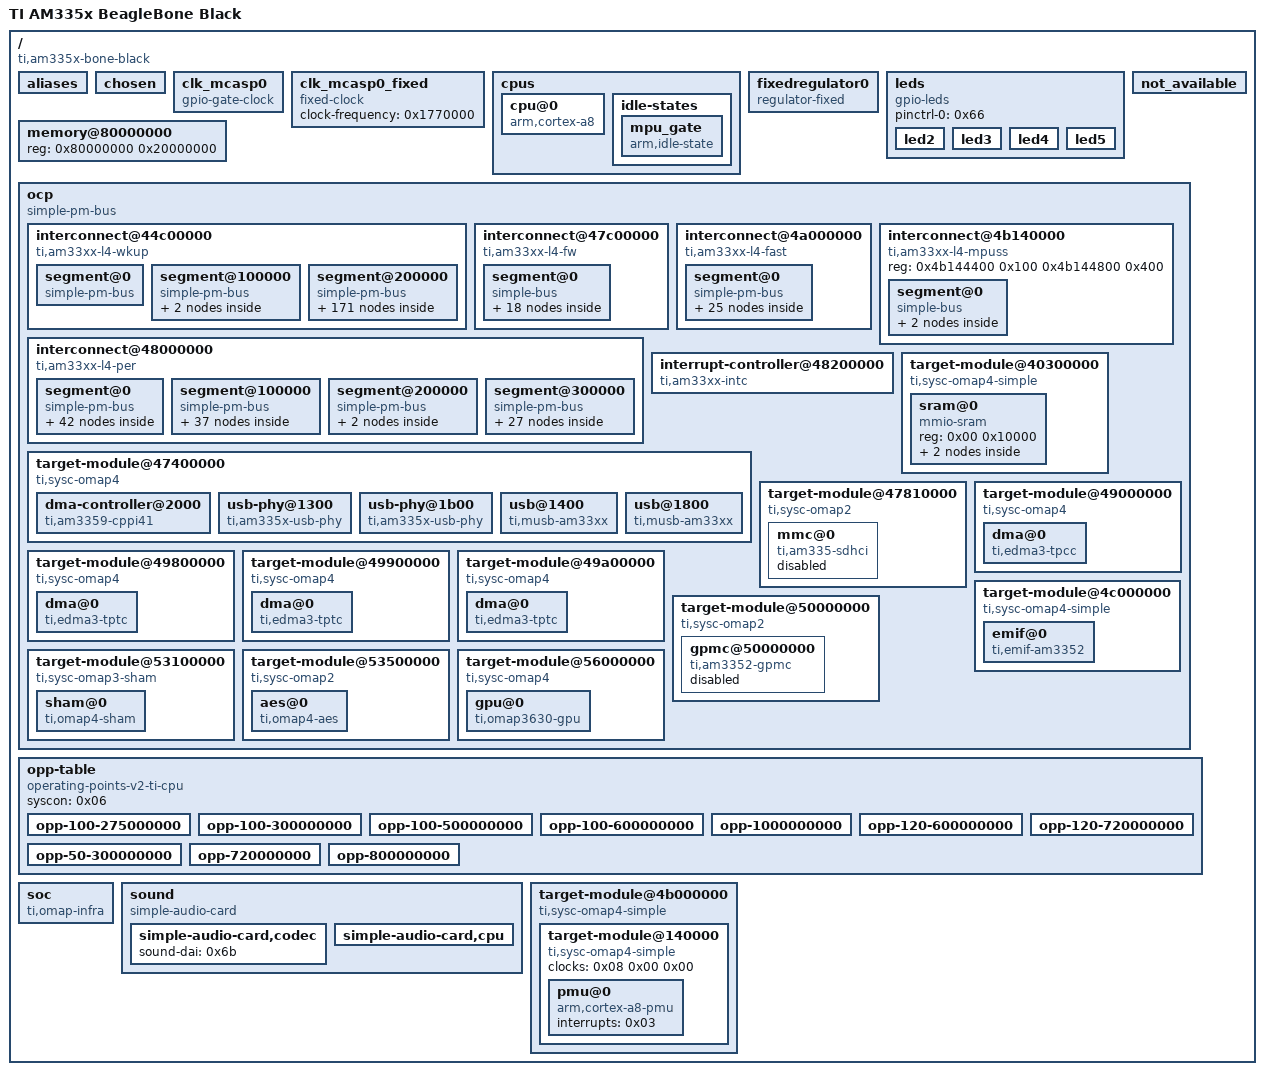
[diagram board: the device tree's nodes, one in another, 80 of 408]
/dts-v1/;

/ {
	#address-cells = <0x01>;
	#size-cells = <0x01>;
	compatible = "ti,am335x-bone-black\0ti,am335x-bone\0ti,am33xx";
	interrupt-parent = <0x01>;
	model = "TI AM335x BeagleBone Black";

	__symbols__ {
		adc_tsc_fck = "/ocp/interconnect@44c00000/segment@200000/target-module@10000/scm@0/scm_conf@0/clocks/clock-adc-tsc-fck";
		aes = "/ocp/target-module@53500000/aes@0";
		aes0_fck = "/ocp/interconnect@44c00000/segment@200000/target-module@10000/scm@0/scm_conf@0/clocks/clock-aes0-fck";
		aes_target = "/ocp/target-module@53500000";
		am335x_adc = "/ocp/interconnect@44c00000/segment@200000/target-module@d000/tscadc@0/adc";
		am33xx_pinmux = "/ocp/interconnect@44c00000/segment@200000/target-module@10000/scm@0/pinmux@800";
		baseboard_data = "/ocp/interconnect@44c00000/segment@200000/target-module@b000/i2c@0/eeprom@50/nvmem-layout/baseboard_data@0";
		baseboard_eeprom = "/ocp/interconnect@44c00000/segment@200000/target-module@b000/i2c@0/eeprom@50";
		bborg_comms_can_pins = "/ocp/interconnect@44c00000/segment@200000/target-module@10000/scm@0/pinmux@800/pinmux_comms_can_pins";
		bborg_comms_rs485_pins = "/ocp/interconnect@44c00000/segment@200000/target-module@10000/scm@0/pinmux@800/pinmux_comms_rs485_pins";
		bone_adc = "/ocp/interconnect@44c00000/segment@200000/target-module@d000/tscadc@0";
		bone_can_1 = "/ocp/interconnect@48000000/segment@100000/target-module@d0000/can@0";
		bone_pinmux = "/ocp/interconnect@44c00000/segment@200000/target-module@10000/scm@0/pinmux@800";
		bone_uart_4 = "/ocp/interconnect@48000000/segment@100000/target-module@a8000/serial@0";
		cape0_data = "/ocp/interconnect@48000000/segment@100000/target-module@9c000/i2c@0/eeprom@54/nvmem-layout/cape_data@0";
		cape1_data = "/ocp/interconnect@48000000/segment@100000/target-module@9c000/i2c@0/eeprom@55/nvmem-layout/cape_data@0";
		cape2_data = "/ocp/interconnect@48000000/segment@100000/target-module@9c000/i2c@0/eeprom@56/nvmem-layout/cape_data@0";
		cape3_data = "/ocp/interconnect@48000000/segment@100000/target-module@9c000/i2c@0/eeprom@57/nvmem-layout/cape_data@0";
		cape_eeprom0 = "/ocp/interconnect@48000000/segment@100000/target-module@9c000/i2c@0/eeprom@54";
		cape_eeprom1 = "/ocp/interconnect@48000000/segment@100000/target-module@9c000/i2c@0/eeprom@55";
		cape_eeprom2 = "/ocp/interconnect@48000000/segment@100000/target-module@9c000/i2c@0/eeprom@56";
		cape_eeprom3 = "/ocp/interconnect@48000000/segment@100000/target-module@9c000/i2c@0/eeprom@57";
		clk_24mhz = "/ocp/interconnect@44c00000/segment@200000/target-module@0/prcm@0/clocks/clock-clk-24mhz";
		clk_24mhz_clkctrl = "/ocp/interconnect@44c00000/segment@200000/target-module@0/prcm@0/clock@0/clock@14c";
		clk_32768_ck = "/ocp/interconnect@44c00000/segment@200000/target-module@0/prcm@0/clocks/clock-clk-32768";
		clk_mcasp0 = "/clk_mcasp0";
		clk_mcasp0_fixed = "/clk_mcasp0_fixed";
		clk_rc32k_ck = "/ocp/interconnect@44c00000/segment@200000/target-module@0/prcm@0/clocks/clock-clk-rc32k";
		clkdiv32k_ck = "/ocp/interconnect@44c00000/segment@200000/target-module@0/prcm@0/clocks/clock-clkdiv32k";
		clkout2_ck = "/ocp/interconnect@44c00000/segment@200000/target-module@0/prcm@0/clocks/clock@700/clock-clkout2@7";
		clkout2_div_ck = "/ocp/interconnect@44c00000/segment@200000/target-module@0/prcm@0/clocks/clock@700/clock-clkout2-div@3";
		cppi41dma = "/ocp/target-module@47400000/dma-controller@2000";
		cpsw_125mhz_clkctrl = "/ocp/interconnect@44c00000/segment@200000/target-module@0/prcm@0/clock@0/clock@0";
		cpsw_125mhz_gclk = "/ocp/interconnect@44c00000/segment@200000/target-module@0/prcm@0/clocks/clock-cpsw-125mhz-gclk";
		cpsw_cpts_rft_clk = "/ocp/interconnect@44c00000/segment@200000/target-module@0/prcm@0/clocks/clock-cpsw-cpts-rft@520";
		cpsw_default = "/ocp/interconnect@44c00000/segment@200000/target-module@10000/scm@0/pinmux@800/cpsw-default-pins";
		cpsw_emac0 = "/ocp/interconnect@4a000000/segment@0/target-module@100000/ethernet@0/slave@200";
		cpsw_emac1 = "/ocp/interconnect@4a000000/segment@0/target-module@100000/ethernet@0/slave@300";
		cpsw_port1 = "/ocp/interconnect@4a000000/segment@0/target-module@100000/switch@0/ethernet-ports/port@1";
		cpsw_port2 = "/ocp/interconnect@4a000000/segment@0/target-module@100000/switch@0/ethernet-ports/port@2";
		cpsw_sleep = "/ocp/interconnect@44c00000/segment@200000/target-module@10000/scm@0/pinmux@800/cpsw-sleep-pins";
		cpu = "/cpus/cpu@0";
		cpu0_opp_table = "/opp-table";
		dailink0_master = "/sound/simple-audio-card,cpu";
		davinci_mdio = "/ocp/interconnect@4a000000/segment@0/target-module@100000/ethernet@0/mdio@1000";
		davinci_mdio_default = "/ocp/interconnect@44c00000/segment@200000/target-module@10000/scm@0/pinmux@800/davinci-mdio-default-pins";
		davinci_mdio_sleep = "/ocp/interconnect@44c00000/segment@200000/target-module@10000/scm@0/pinmux@800/davinci-mdio-sleep-pins";
		davinci_mdio_sw = "/ocp/interconnect@4a000000/segment@0/target-module@100000/switch@0/mdio@1000";
		dcan0 = "/ocp/interconnect@48000000/segment@100000/target-module@cc000/can@0";
		dcan0_fck = "/ocp/interconnect@44c00000/segment@200000/target-module@10000/scm@0/scm_conf@0/clocks/clock-dcan0-fck";
		dcan1 = "/ocp/interconnect@48000000/segment@100000/target-module@d0000/can@0";
		dcan1_fck = "/ocp/interconnect@44c00000/segment@200000/target-module@10000/scm@0/scm_conf@0/clocks/clock-dcan1-fck";
		dcdc1_reg = "/ocp/interconnect@44c00000/segment@200000/target-module@b000/i2c@0/pmic@24/regulators/regulator@0";
		dcdc2_reg = "/ocp/interconnect@44c00000/segment@200000/target-module@b000/i2c@0/pmic@24/regulators/regulator@1";
		dcdc3_reg = "/ocp/interconnect@44c00000/segment@200000/target-module@b000/i2c@0/pmic@24/regulators/regulator@2";
		dpll_core_ck = "/ocp/interconnect@44c00000/segment@200000/target-module@0/prcm@0/clocks/clock@490";
		dpll_core_m4_ck = "/ocp/interconnect@44c00000/segment@200000/target-module@0/prcm@0/clocks/clock-dpll-core-m4@480";
		dpll_core_m4_div2_ck = "/ocp/interconnect@44c00000/segment@200000/target-module@0/prcm@0/clocks/clock-dpll-core-m4-div2";
		dpll_core_m5_ck = "/ocp/interconnect@44c00000/segment@200000/target-module@0/prcm@0/clocks/clock-dpll-core-m5@484";
		dpll_core_m6_ck = "/ocp/interconnect@44c00000/segment@200000/target-module@0/prcm@0/clocks/clock-dpll-core-m6@4d8";
		dpll_core_x2_ck = "/ocp/interconnect@44c00000/segment@200000/target-module@0/prcm@0/clocks/clock-dpll-core-x2";
		dpll_ddr_ck = "/ocp/interconnect@44c00000/segment@200000/target-module@0/prcm@0/clocks/clock@494";
		dpll_ddr_m2_ck = "/ocp/interconnect@44c00000/segment@200000/target-module@0/prcm@0/clocks/clock-dpll-ddr-m2@4a0";
		dpll_ddr_m2_div2_ck = "/ocp/interconnect@44c00000/segment@200000/target-module@0/prcm@0/clocks/clock-dpll-ddr-m2-div2";
		dpll_disp_ck = "/ocp/interconnect@44c00000/segment@200000/target-module@0/prcm@0/clocks/clock@498";
		dpll_disp_m2_ck = "/ocp/interconnect@44c00000/segment@200000/target-module@0/prcm@0/clocks/clock-dpll-disp-m2@4a4";
		dpll_mpu_ck = "/ocp/interconnect@44c00000/segment@200000/target-module@0/prcm@0/clocks/clock@488";
		dpll_mpu_m2_ck = "/ocp/interconnect@44c00000/segment@200000/target-module@0/prcm@0/clocks/clock-dpll-mpu-m2@4a8";
		dpll_per_ck = "/ocp/interconnect@44c00000/segment@200000/target-module@0/prcm@0/clocks/clock@48c";
		dpll_per_m2_ck = "/ocp/interconnect@44c00000/segment@200000/target-module@0/prcm@0/clocks/clock-dpll-per-m2@4ac";
		dpll_per_m2_div4_ck = "/ocp/interconnect@44c00000/segment@200000/target-module@0/prcm@0/clocks/clock-dpll-per-m2-div4";
		dpll_per_m2_div4_wkupdm_ck = "/ocp/interconnect@44c00000/segment@200000/target-module@0/prcm@0/clocks/clock-dpll-per-m2-div4-wkupdm";
		ecap0 = "/ocp/interconnect@48000000/segment@300000/target-module@0/epwmss@0/pwm@100";
		ecap1 = "/ocp/interconnect@48000000/segment@300000/target-module@2000/epwmss@0/pwm@100";
		ecap2 = "/ocp/interconnect@48000000/segment@300000/target-module@4000/epwmss@0/pwm@100";
		edma = "/ocp/target-module@49000000/dma@0";
		edma_tptc0 = "/ocp/target-module@49800000/dma@0";
		edma_tptc1 = "/ocp/target-module@49900000/dma@0";
		edma_tptc2 = "/ocp/target-module@49a00000/dma@0";
		edma_xbar = "/ocp/interconnect@44c00000/segment@200000/target-module@10000/scm@0/dma-router@f90";
		ehrpwm0 = "/ocp/interconnect@48000000/segment@300000/target-module@0/epwmss@0/pwm@200";
		ehrpwm0_tbclk = "/ocp/interconnect@44c00000/segment@200000/target-module@10000/scm@0/scm_conf@0/clocks/clock@664/clock-ehrpwm0-tbclk@0";
		ehrpwm1 = "/ocp/interconnect@48000000/segment@300000/target-module@2000/epwmss@0/pwm@200";
		ehrpwm1_tbclk = "/ocp/interconnect@44c00000/segment@200000/target-module@10000/scm@0/scm_conf@0/clocks/clock@664/clock-ehrpwm1-tbclk@1";
		ehrpwm2 = "/ocp/interconnect@48000000/segment@300000/target-module@4000/epwmss@0/pwm@200";
		ehrpwm2_tbclk = "/ocp/interconnect@44c00000/segment@200000/target-module@10000/scm@0/scm_conf@0/clocks/clock@664/clock-ehrpwm2-tbclk@2";
		elm = "/ocp/interconnect@48000000/segment@0/target-module@80000/elm@0";
		emif = "/ocp/target-module@4c000000/emif@0";
		emmc_pins = "/ocp/interconnect@44c00000/segment@200000/target-module@10000/scm@0/pinmux@800/emmc-pins";
		epwmss0 = "/ocp/interconnect@48000000/segment@300000/target-module@0/epwmss@0";
		epwmss1 = "/ocp/interconnect@48000000/segment@300000/target-module@2000/epwmss@0";
		epwmss2 = "/ocp/interconnect@48000000/segment@300000/target-module@4000/epwmss@0";
		eqep0 = "/ocp/interconnect@48000000/segment@300000/target-module@0/epwmss@0/counter@180";
		eqep1 = "/ocp/interconnect@48000000/segment@300000/target-module@2000/epwmss@0/counter@180";
		eqep2 = "/ocp/interconnect@48000000/segment@300000/target-module@4000/epwmss@0/counter@180";
		ethphy0 = "/ocp/interconnect@4a000000/segment@0/target-module@100000/switch@0/mdio@1000/ethernet-phy@0";
		gfx_fck_div_ck = "/ocp/interconnect@44c00000/segment@200000/target-module@0/prcm@0/clocks/clock@52c/clock-gfx-fck-div@0";
		gfx_fclk_clksel_ck = "/ocp/interconnect@44c00000/segment@200000/target-module@0/prcm@0/clocks/clock@52c/clock-gfx-fclk-clksel@1";
		gfx_l3_clkctrl = "/ocp/interconnect@44c00000/segment@200000/target-module@0/prcm@0/clock@900/clock@0";
		gfx_l3_cm = "/ocp/interconnect@44c00000/segment@200000/target-module@0/prcm@0/clock@900";
		gpio0 = "/ocp/interconnect@44c00000/segment@200000/target-module@7000/gpio@0";
		gpio0_dbclk_mux_ck = "/ocp/interconnect@44c00000/segment@200000/target-module@0/prcm@0/clocks/clock-gpio0-dbclk-mux@53c";
		gpio0_target = "/ocp/interconnect@44c00000/segment@200000/target-module@7000";
		gpio1 = "/ocp/interconnect@48000000/segment@0/target-module@4c000/gpio@0";
		gpio2 = "/ocp/interconnect@48000000/segment@100000/target-module@ac000/gpio@0";
		gpio3 = "/ocp/interconnect@48000000/segment@100000/target-module@ae000/gpio@0";
		gpio3_target = "/ocp/interconnect@48000000/segment@100000/target-module@ae000";
		gpmc = "/ocp/target-module@50000000/gpmc@50000000";
		hdmi_0 = "/ocp/interconnect@44c00000/segment@200000/target-module@b000/i2c@0/tda19988@70/ports/port@0/endpoint";
		hwspinlock = "/ocp/interconnect@48000000/segment@0/target-module@ca000/spinlock@0";
		i2c0 = "/ocp/interconnect@44c00000/segment@200000/target-module@b000/i2c@0";
		i2c0_pins = "/ocp/interconnect@44c00000/segment@200000/target-module@10000/scm@0/pinmux@800/i2c0-pins";
		i2c1 = "/ocp/interconnect@48000000/segment@0/target-module@2a000/i2c@0";
		i2c2 = "/ocp/interconnect@48000000/segment@100000/target-module@9c000/i2c@0";
		i2c2_pins = "/ocp/interconnect@44c00000/segment@200000/target-module@10000/scm@0/pinmux@800/i2c2-pins";
		ieee5000_fck = "/ocp/interconnect@44c00000/segment@200000/target-module@0/prcm@0/clocks/clock-ieee5000-fck-1@e4";
		intc = "/ocp/interrupt-controller@48200000";
		l3_aon_clkctrl = "/ocp/interconnect@44c00000/segment@200000/target-module@0/prcm@0/clock@400/clock@14";
		l3_clkctrl = "/ocp/interconnect@44c00000/segment@200000/target-module@0/prcm@0/clock@0/clock@24";
		l3_gclk = "/ocp/interconnect@44c00000/segment@200000/target-module@0/prcm@0/clocks/clock-l3-gclk";
		l3s_clkctrl = "/ocp/interconnect@44c00000/segment@200000/target-module@0/prcm@0/clock@0/clock@1c";
		l3s_gclk = "/ocp/interconnect@44c00000/segment@200000/target-module@0/prcm@0/clocks/clock-l3s-gclk";
		l4_cefuse_clkctrl = "/ocp/interconnect@44c00000/segment@200000/target-module@0/prcm@0/clock@a00/clock@0";
		l4_cefuse_cm = "/ocp/interconnect@44c00000/segment@200000/target-module@0/prcm@0/clock@a00";
		l4_fast = "/ocp/interconnect@4a000000";
		l4_fw = "/ocp/interconnect@47c00000";
		l4_mpuss = "/ocp/interconnect@4b140000";
		l4_per = "/ocp/interconnect@48000000";
		l4_rtc_clkctrl = "/ocp/interconnect@44c00000/segment@200000/target-module@0/prcm@0/clock@800/clock@0";
		l4_rtc_cm = "/ocp/interconnect@44c00000/segment@200000/target-module@0/prcm@0/clock@800";
		l4_rtc_gclk = "/ocp/interconnect@44c00000/segment@200000/target-module@0/prcm@0/clocks/clock-l4-rtc-gclk";
		l4_wkup = "/ocp/interconnect@44c00000";
		l4_wkup_aon_clkctrl = "/ocp/interconnect@44c00000/segment@200000/target-module@0/prcm@0/clock@400/clock@b0";
		l4_wkup_clkctrl = "/ocp/interconnect@44c00000/segment@200000/target-module@0/prcm@0/clock@400/clock@0";
		l4fw_gclk = "/ocp/interconnect@44c00000/segment@200000/target-module@0/prcm@0/clocks/clock-l4fw-gclk";
		l4hs_clkctrl = "/ocp/interconnect@44c00000/segment@200000/target-module@0/prcm@0/clock@0/clock@120";
		l4hs_gclk = "/ocp/interconnect@44c00000/segment@200000/target-module@0/prcm@0/clocks/clock-l4hs-gclk";
		l4ls_clkctrl = "/ocp/interconnect@44c00000/segment@200000/target-module@0/prcm@0/clock@0/clock@38";
		l4ls_gclk = "/ocp/interconnect@44c00000/segment@200000/target-module@0/prcm@0/clocks/clock-l4ls-gclk";
		lcd_gclk = "/ocp/interconnect@44c00000/segment@200000/target-module@0/prcm@0/clocks/clock-lcd-gclk@534";
		lcdc = "/ocp/interconnect@48000000/segment@300000/target-module@e000/lcdc@0";
		lcdc_0 = "/ocp/interconnect@48000000/segment@300000/target-module@e000/lcdc@0/port/endpoint@0";
		lcdc_clkctrl = "/ocp/interconnect@44c00000/segment@200000/target-module@0/prcm@0/clock@0/clock@18";
		ldo1_reg = "/ocp/interconnect@44c00000/segment@200000/target-module@b000/i2c@0/pmic@24/regulators/regulator@3";
		ldo2_reg = "/ocp/interconnect@44c00000/segment@200000/target-module@b000/i2c@0/pmic@24/regulators/regulator@4";
		ldo3_reg = "/ocp/interconnect@44c00000/segment@200000/target-module@b000/i2c@0/pmic@24/regulators/regulator@5";
		ldo4_reg = "/ocp/interconnect@44c00000/segment@200000/target-module@b000/i2c@0/pmic@24/regulators/regulator@6";
		mac = "/ocp/interconnect@4a000000/segment@0/target-module@100000/ethernet@0";
		mac_sw = "/ocp/interconnect@4a000000/segment@0/target-module@100000/switch@0";
		mailbox = "/ocp/interconnect@48000000/segment@0/target-module@c8000/mailbox@0";
		mbox_wkupm3 = "/ocp/interconnect@48000000/segment@0/target-module@c8000/mailbox@0/mbox-wkup-m3";
		mcasp0 = "/ocp/interconnect@48000000/segment@0/target-module@38000/mcasp@0";
		mcasp0_fck = "/ocp/interconnect@44c00000/segment@200000/target-module@10000/scm@0/scm_conf@0/clocks/clock-mcasp0-fck";
		mcasp0_pins = "/ocp/interconnect@44c00000/segment@200000/target-module@10000/scm@0/pinmux@800/mcasp0-pins";
		mcasp1 = "/ocp/interconnect@48000000/segment@0/target-module@3c000/mcasp@0";
		mcasp1_fck = "/ocp/interconnect@44c00000/segment@200000/target-module@10000/scm@0/scm_conf@0/clocks/clock-mcasp1-fck";
		mmc1 = "/ocp/interconnect@48000000/segment@0/target-module@60000/mmc@0";
		mmc1_pins = "/ocp/interconnect@44c00000/segment@200000/target-module@10000/scm@0/pinmux@800/mmc1-pins";
		mmc2 = "/ocp/interconnect@48000000/segment@100000/target-module@d8000/mmc@0";
		mmc3 = "/ocp/target-module@47810000/mmc@0";
		mmc_clk = "/ocp/interconnect@44c00000/segment@200000/target-module@0/prcm@0/clocks/clock-mmc";
		mmu_fck = "/ocp/interconnect@44c00000/segment@200000/target-module@0/prcm@0/clocks/clock-mmu-fck-1@914";
		mpu_clkctrl = "/ocp/interconnect@44c00000/segment@200000/target-module@0/prcm@0/clock@600/clock@0";
		mpu_cm = "/ocp/interconnect@44c00000/segment@200000/target-module@0/prcm@0/clock@600";
		mpu_gate = "/cpus/idle-states/mpu_gate";
		not_available = "/not_available";
		nxp_hdmi_bonelt_off_pins = "/ocp/interconnect@44c00000/segment@200000/target-module@10000/scm@0/pinmux@800/nxp-hdmi-bonelt-off-pins";
		nxp_hdmi_bonelt_pins = "/ocp/interconnect@44c00000/segment@200000/target-module@10000/scm@0/pinmux@800/nxp-hdmi-bonelt-pins";
		ocmcram = "/ocp/target-module@40300000/sram@0";
		ocp = "/ocp";
		per_cm = "/ocp/interconnect@44c00000/segment@200000/target-module@0/prcm@0/clock@0";
		phy_gmii_sel = "/ocp/interconnect@44c00000/segment@200000/target-module@10000/scm@0/scm_conf@0/phy-gmii-sel";
		pm_sram_code = "/ocp/target-module@40300000/sram@0/pm-code-sram@0";
		pm_sram_data = "/ocp/target-module@40300000/sram@0/pm-data-sram@1000";
		prcm = "/ocp/interconnect@44c00000/segment@200000/target-module@0/prcm@0";
		prcm_clockdomains = "/ocp/interconnect@44c00000/segment@200000/target-module@0/prcm@0/clockdomains";
		prcm_clocks = "/ocp/interconnect@44c00000/segment@200000/target-module@0/prcm@0/clocks";
		prm_cefuse = "/ocp/interconnect@44c00000/segment@200000/target-module@0/prcm@0/prm@1200";
		prm_device = "/ocp/interconnect@44c00000/segment@200000/target-module@0/prcm@0/prm@f00";
		prm_gfx = "/ocp/interconnect@44c00000/segment@200000/target-module@0/prcm@0/prm@1100";
		prm_mpu = "/ocp/interconnect@44c00000/segment@200000/target-module@0/prcm@0/prm@e00";
		prm_per = "/ocp/interconnect@44c00000/segment@200000/target-module@0/prcm@0/prm@c00";
		prm_rtc = "/ocp/interconnect@44c00000/segment@200000/target-module@0/prcm@0/prm@1000";
		prm_wkup = "/ocp/interconnect@44c00000/segment@200000/target-module@0/prcm@0/prm@d00";
		pru0 = "/ocp/interconnect@4a000000/segment@0/target-module@300000/pruss@0/pru@34000";
		pru1 = "/ocp/interconnect@4a000000/segment@0/target-module@300000/pruss@0/pru@38000";
		pruss = "/ocp/interconnect@4a000000/segment@0/target-module@300000/pruss@0";
		pruss_cfg = "/ocp/interconnect@4a000000/segment@0/target-module@300000/pruss@0/cfg@26000";
		pruss_iepclk_mux = "/ocp/interconnect@4a000000/segment@0/target-module@300000/pruss@0/cfg@26000/clocks/iepclk-mux@30";
		pruss_intc = "/ocp/interconnect@4a000000/segment@0/target-module@300000/pruss@0/interrupt-controller@20000";
		pruss_mdio = "/ocp/interconnect@4a000000/segment@0/target-module@300000/pruss@0/mdio@32400";
		pruss_mem = "/ocp/interconnect@4a000000/segment@0/target-module@300000/pruss@0/memories@0";
		pruss_mii_rt = "/ocp/interconnect@4a000000/segment@0/target-module@300000/pruss@0/mii-rt@32000";
		pruss_ocp_clkctrl = "/ocp/interconnect@44c00000/segment@200000/target-module@0/prcm@0/clock@0/clock@e8";
		pruss_ocp_gclk = "/ocp/interconnect@44c00000/segment@200000/target-module@0/prcm@0/clocks/clock-pruss-ocp-gclk@530";
		pruss_tm = "/ocp/interconnect@4a000000/segment@0/target-module@300000";
		rng = "/ocp/interconnect@48000000/segment@300000/target-module@10000/rng@0";
		rng_fck = "/ocp/interconnect@44c00000/segment@200000/target-module@10000/scm@0/scm_conf@0/clocks/clock-rng-fck";
		rtc = "/ocp/interconnect@44c00000/segment@200000/target-module@3e000/rtc@0";
		scm = "/ocp/interconnect@44c00000/segment@200000/target-module@10000/scm@0";
		scm_clockdomains = "/ocp/interconnect@44c00000/segment@200000/target-module@10000/scm@0/clockdomains";
		scm_clocks = "/ocp/interconnect@44c00000/segment@200000/target-module@10000/scm@0/scm_conf@0/clocks";
		scm_conf = "/ocp/interconnect@44c00000/segment@200000/target-module@10000/scm@0/scm_conf@0";
		sha0_fck = "/ocp/interconnect@44c00000/segment@200000/target-module@10000/scm@0/scm_conf@0/clocks/clock-sha0-fck";
		sham = "/ocp/target-module@53100000/sham@0";
		sham_target = "/ocp/target-module@53100000";
		smartreflex0_fck = "/ocp/interconnect@44c00000/segment@200000/target-module@10000/scm@0/scm_conf@0/clocks/clock-smartreflex0-fck";
		smartreflex1_fck = "/ocp/interconnect@44c00000/segment@200000/target-module@10000/scm@0/scm_conf@0/clocks/clock-smartreflex1-fck";
		spi0 = "/ocp/interconnect@48000000/segment@0/target-module@30000/spi@0";
		spi0_alt_pins = "/ocp/interconnect@44c00000/segment@200000/target-module@10000/scm@0/pinmux@800/spi0-alt-pins";
		spi1 = "/ocp/interconnect@48000000/segment@100000/target-module@a0000/spi@0";
		ssd1306_spi_pins = "/ocp/interconnect@44c00000/segment@200000/target-module@10000/scm@0/pinmux@800/ssd1306-spi-pins";
		sys_clkin_ck = "/ocp/interconnect@44c00000/segment@200000/target-module@10000/scm@0/scm_conf@0/clocks/clock-sys-clkin-22@40";
		sysclk_div_ck = "/ocp/interconnect@44c00000/segment@200000/target-module@0/prcm@0/clocks/clock-sysclk-div";
		sysclkout_pre_ck = "/ocp/interconnect@44c00000/segment@200000/target-module@0/prcm@0/clocks/clock@700/clock-sysclkout-pre@0";
		tclkin_ck = "/ocp/interconnect@44c00000/segment@200000/target-module@0/prcm@0/clocks/clock-tclkin";
		tda19988 = "/ocp/interconnect@44c00000/segment@200000/target-module@b000/i2c@0/tda19988@70";
		timer1 = "/ocp/interconnect@44c00000/segment@200000/target-module@31000/timer@0";
		timer1_fck = "/ocp/interconnect@44c00000/segment@200000/target-module@0/prcm@0/clocks/clock-timer1-fck@528";
		timer1_target = "/ocp/interconnect@44c00000/segment@200000/target-module@31000";
		timer2 = "/ocp/interconnect@48000000/segment@0/target-module@40000/timer@0";
		timer2_fck = "/ocp/interconnect@44c00000/segment@200000/target-module@0/prcm@0/clocks/clock-timer2-fck@508";
		timer2_target = "/ocp/interconnect@48000000/segment@0/target-module@40000";
		timer3 = "/ocp/interconnect@48000000/segment@0/target-module@42000/timer@0";
		timer3_fck = "/ocp/interconnect@44c00000/segment@200000/target-module@0/prcm@0/clocks/clock-timer3-fck@50c";
		timer4 = "/ocp/interconnect@48000000/segment@0/target-module@44000/timer@0";
		timer4_fck = "/ocp/interconnect@44c00000/segment@200000/target-module@0/prcm@0/clocks/clock-timer4-fck@510";
		timer5 = "/ocp/interconnect@48000000/segment@0/target-module@46000/timer@0";
		timer5_fck = "/ocp/interconnect@44c00000/segment@200000/target-module@0/prcm@0/clocks/clock-timer5-fck@518";
		timer6 = "/ocp/interconnect@48000000/segment@0/target-module@48000/timer@0";
		timer6_fck = "/ocp/interconnect@44c00000/segment@200000/target-module@0/prcm@0/clocks/clock-timer6-fck@51c";
		timer7 = "/ocp/interconnect@48000000/segment@0/target-module@4a000/timer@0";
		timer7_fck = "/ocp/interconnect@44c00000/segment@200000/target-module@0/prcm@0/clocks/clock-timer7-fck@504";
		tps = "/ocp/interconnect@44c00000/segment@200000/target-module@b000/i2c@0/pmic@24";
		tscadc = "/ocp/interconnect@44c00000/segment@200000/target-module@d000/tscadc@0";
		uart0 = "/ocp/interconnect@44c00000/segment@200000/target-module@9000/serial@0";
		uart0_pins = "/ocp/interconnect@44c00000/segment@200000/target-module@10000/scm@0/pinmux@800/uart0-pins";
		uart1 = "/ocp/interconnect@48000000/segment@0/target-module@22000/serial@0";
		uart2 = "/ocp/interconnect@48000000/segment@0/target-module@24000/serial@0";
		uart3 = "/ocp/interconnect@48000000/segment@100000/target-module@a6000/serial@0";
		uart4 = "/ocp/interconnect@48000000/segment@100000/target-module@a8000/serial@0";
		uart5 = "/ocp/interconnect@48000000/segment@100000/target-module@aa000/serial@0";
		usb = "/ocp/target-module@47400000";
		usb0 = "/ocp/target-module@47400000/usb@1400";
		usb0_phy = "/ocp/target-module@47400000/usb-phy@1300";
		usb1 = "/ocp/target-module@47400000/usb@1800";
		usb1_phy = "/ocp/target-module@47400000/usb-phy@1b00";
		usb_ctrl_mod = "/ocp/interconnect@44c00000/segment@200000/target-module@10000/scm@0/control@620";
		usbotg_fck = "/ocp/interconnect@44c00000/segment@200000/target-module@0/prcm@0/clocks/clock-usbotg-fck-8@47c";
		user_leds_s0 = "/ocp/interconnect@44c00000/segment@200000/target-module@10000/scm@0/pinmux@800/user-leds-s0-pins";
		virt_19200000_ck = "/ocp/interconnect@44c00000/segment@200000/target-module@0/prcm@0/clocks/clock-virt-19200000";
		virt_24000000_ck = "/ocp/interconnect@44c00000/segment@200000/target-module@0/prcm@0/clocks/clock-virt-24000000";
		virt_25000000_ck = "/ocp/interconnect@44c00000/segment@200000/target-module@0/prcm@0/clocks/clock-virt-25000000";
		virt_26000000_ck = "/ocp/interconnect@44c00000/segment@200000/target-module@0/prcm@0/clocks/clock-virt-26000000";
		vmmcsd_fixed = "/fixedregulator0";
		wdt1_fck = "/ocp/interconnect@44c00000/segment@200000/target-module@0/prcm@0/clocks/clock-wdt1-fck@538";
		wdt2 = "/ocp/interconnect@44c00000/segment@200000/target-module@35000/wdt@0";
		wkup_cm = "/ocp/interconnect@44c00000/segment@200000/target-module@0/prcm@0/clock@400";
		wkup_m3 = "/ocp/interconnect@44c00000/segment@100000/target-module@0/cpu@0";
		wkup_m3_ipc = "/ocp/interconnect@44c00000/segment@200000/target-module@10000/scm@0/wkup_m3_ipc@1324";
	};

	aliases {
		d-can0 = "/ocp/interconnect@48000000/segment@100000/target-module@cc000/can@0";
		d-can1 = "/ocp/interconnect@48000000/segment@100000/target-module@d0000/can@0";
		ethernet0 = "/ocp/interconnect@4a000000/segment@0/target-module@100000/switch@0/ethernet-ports/port@1";
		ethernet1 = "/ocp/interconnect@4a000000/segment@0/target-module@100000/switch@0/ethernet-ports/port@2";
		i2c0 = "/ocp/interconnect@44c00000/segment@200000/target-module@b000/i2c@0";
		i2c1 = "/ocp/interconnect@48000000/segment@0/target-module@2a000/i2c@0";
		i2c2 = "/ocp/interconnect@48000000/segment@100000/target-module@9c000/i2c@0";
		mmc0 = "/ocp/interconnect@48000000/segment@0/target-module@60000/mmc@0";
		mmc1 = "/ocp/interconnect@48000000/segment@100000/target-module@d8000/mmc@0";
		mmc2 = "/ocp/target-module@47810000/mmc@0";
		phy0 = "/ocp/target-module@47400000/usb-phy@1300";
		phy1 = "/ocp/target-module@47400000/usb-phy@1b00";
		serial0 = "/ocp/interconnect@44c00000/segment@200000/target-module@9000/serial@0";
		serial1 = "/ocp/interconnect@48000000/segment@0/target-module@22000/serial@0";
		serial2 = "/ocp/interconnect@48000000/segment@0/target-module@24000/serial@0";
		serial3 = "/ocp/interconnect@48000000/segment@100000/target-module@a6000/serial@0";
		serial4 = "/ocp/interconnect@48000000/segment@100000/target-module@a8000/serial@0";
		serial5 = "/ocp/interconnect@48000000/segment@100000/target-module@aa000/serial@0";
		spi0 = "/ocp/interconnect@48000000/segment@0/target-module@30000/spi@0";
		spi1 = "/ocp/interconnect@48000000/segment@100000/target-module@a0000/spi@0";
		usb0 = "/ocp/target-module@47400000/usb@1400";
		usb1 = "/ocp/target-module@47400000/usb@1800";
	};

	chosen {
		base_dtb = "am335x-boneblack.dts";
		base_dtb_timestamp = "Mon Aug 17 11:34:50 2026";
		stdout-path = "serial0:115200n8";
	};

	clk_mcasp0 {
		#clock-cells = <0x00>;
		clocks = <0x67>;
		compatible = "gpio-gate-clock";
		enable-gpios = <0x28 0x1b 0x00>;
		phandle = <0x6a>;
	};

	clk_mcasp0_fixed {
		#clock-cells = <0x00>;
		clock-frequency = <0x1770000>;
		compatible = "fixed-clock";
		phandle = <0x67>;
	};

	cpus {
		#address-cells = <0x01>;
		#size-cells = <0x00>;

		cpu@0 {
			clock-latency = <0x493e0>;
			clock-names = "cpu";
			clocks = <0x03>;
			compatible = "arm,cortex-a8";
			cpu-idle-states = <0x04>;
			cpu0-supply = <0x05>;
			device_type = "cpu";
			enable-method = "ti,am3352";
			operating-points-v2 = <0x02>;
			phandle = <0x6c>;
			reg = <0x00>;
		};

		idle-states {

			mpu_gate {
				compatible = "arm,idle-state";
				entry-latency-us = <0x28>;
				exit-latency-us = <0x5a>;
				min-residency-us = <0x12c>;
				phandle = <0x04>;
				ti,idle-wkup-m3;
			};
		};
	};

	fixedregulator0 {
		compatible = "regulator-fixed";
		phandle = <0x40>;
		regulator-max-microvolt = <0x325aa0>;
		regulator-min-microvolt = <0x325aa0>;
		regulator-name = "vmmcsd_fixed";
	};

	leds {
		compatible = "gpio-leds";
		pinctrl-0 = <0x66>;
		pinctrl-names = "default";

		led2 {
			default-state = "off";
			gpios = <0x28 0x15 0x00>;
			label = "beaglebone:green:usr0";
			linux,default-trigger = "heartbeat";
		};

		led3 {
			default-state = "off";
			gpios = <0x28 0x16 0x00>;
			label = "beaglebone:green:usr1";
			linux,default-trigger = "mmc0";
		};

		led4 {
			default-state = "off";
			gpios = <0x28 0x17 0x00>;
			label = "beaglebone:green:usr2";
			linux,default-trigger = "cpu0";
		};

		led5 {
			default-state = "off";
			gpios = <0x28 0x18 0x00>;
			label = "beaglebone:green:usr3";
			linux,default-trigger = "mmc1";
		};
	};

	memory@80000000 {
		device_type = "memory";
		reg = <0x80000000 0x20000000>;
	};

	not_available {
		phandle = <0x100>;
	};

	ocp {
		#address-cells = <0x01>;
		#size-cells = <0x01>;
		clock-names = "fck";
		clocks = <0x07 0xbc 0x00>;
		compatible = "simple-pm-bus";
		phandle = <0x6d>;
		power-domains = <0x09>;
		ranges;

		interconnect@44c00000 {
			#address-cells = <0x01>;
			#size-cells = <0x01>;
			clock-names = "fck";
			clocks = <0x0b 0x0c 0x00>;
			compatible = "ti,am33xx-l4-wkup\0simple-pm-bus";
			phandle = <0x6e>;
			power-domains = <0x0a>;
			ranges = <0x00 0x44c00000 0x100000 0x100000 0x44d00000 0x100000 0x200000 0x44e00000 0x100000>;
			reg = <0x44c00000 0x800 0x44c00800 0x800 0x44c01000 0x400 0x44c01400 0x400>;
			reg-names = "ap\0la\0ia0\0ia1";

			segment@0 {
				#address-cells = <0x01>;
				#size-cells = <0x01>;
				compatible = "simple-pm-bus";
				ranges = <0x00 0x00 0x800 0x800 0x800 0x800 0x1000 0x1000 0x400 0x1400 0x1400 0x400>;
			};

			segment@100000 {
				#address-cells = <0x01>;
				#size-cells = <0x01>;
				compatible = "simple-pm-bus";
				ranges = <0x00 0x100000 0x4000 0x4000 0x104000 0x1000 0x80000 0x180000 0x2000 0x82000 0x182000 0x1000>;

				target-module@0 {
					#address-cells = <0x01>;
					#size-cells = <0x01>;
					clock-names = "fck";
					clocks = <0x0c 0x00 0x00>;
					compatible = "ti,sysc-omap4\0ti,sysc";
					ranges = <0x00 0x00 0x4000 0x80000 0x80000 0x2000>;
					reg = <0x00 0x04>;
					reg-names = "rev";

					cpu@0 {
						compatible = "ti,am3352-wkup-m3";
						phandle = <0x32>;
						reg = <0x00 0x4000 0x80000 0x2000>;
						reg-names = "umem\0dmem";
						reset-names = "rstctrl";
						resets = <0x0a 0x03>;
						ti,pm-firmware = "am335x-pm-firmware.elf";
					};
				};
			};

			segment@200000 {
				#address-cells = <0x01>;
				#size-cells = <0x01>;
				compatible = "simple-pm-bus";
				ranges = <0x00 0x200000 0x2000 0x2000 0x202000 0x1000 0x3000 0x203000 0x1000 0x4000 0x204000 0x1000 0x5000 0x205000 0x1000 0x6000 0x206000 0x1000 0x7000 0x207000 0x1000 0x8000 0x208000 0x1000 0x9000 0x209000 0x1000 0xa000 0x20a000 0x1000 0xb000 0x20b000 0x1000 0xc000 0x20c000 0x1000 0xd000 0x20d000 0x1000 0xf000 0x20f000 0x1000 0x10000 0x210000 0x10000 0x20000 0x220000 0x10000 0x30000 0x230000 0x1000 0x31000 0x231000 0x1000 0x32000 0x232000 0x1000 0x33000 0x233000 0x1000 0x34000 0x234000 0x1000 0x35000 0x235000 0x1000 0x36000 0x236000 0x1000 0x37000 0x237000 0x1000 0x38000 0x238000 0x1000 0x39000 0x239000 0x1000 0x3a000 0x23a000 0x1000 0x3e000 0x23e000 0x1000 0x3f000 0x23f000 0x1000 0xe000 0x20e000 0x1000 0x40000 0x240000 0x40000 0x80000 0x280000 0x1000>;

				target-module@0 {
					#address-cells = <0x01>;
					#size-cells = <0x01>;
					compatible = "ti,sysc-omap4\0ti,sysc";
					ranges = <0x00 0x00 0x2000>;
					reg = <0x00 0x04>;
					reg-names = "rev";

					prcm@0 {
						#address-cells = <0x01>;
						#size-cells = <0x01>;
						compatible = "ti,am3-prcm\0simple-bus";
						phandle = <0x6f>;
						ranges = <0x00 0x00 0x2000>;
						reg = <0x00 0x2000>;

						clock@0 {
							#address-cells = <0x01>;
							#size-cells = <0x01>;
							clock-output-names = "per_cm";
							compatible = "ti,omap4-cm";
							phandle = <0x8a>;
							ranges = <0x00 0x00 0x400>;
							reg = <0x00 0x400>;

							clock@0 {
								#clock-cells = <0x02>;
								clock-output-names = "cpsw_125mhz_clkctrl";
								compatible = "ti,clkctrl";
								phandle = <0x51>;
								reg = <0x00 0x18>;
							};

							clock@120 {
								#clock-cells = <0x02>;
								clock-output-names = "l4hs_clkctrl";
								compatible = "ti,clkctrl";
								phandle = <0x50>;
								reg = <0x120 0x04>;
							};

							clock@14c {
								#clock-cells = <0x02>;
								clock-output-names = "clk_24mhz_clkctrl";
								compatible = "ti,clkctrl";
								phandle = <0x19>;
								reg = <0x14c 0x04>;
							};

							clock@18 {
								#clock-cells = <0x02>;
								clock-output-names = "lcdc_clkctrl";
								compatible = "ti,clkctrl";
								phandle = <0x4e>;
								reg = <0x18 0x04>;
							};

							clock@1c {
								#clock-cells = <0x02>;
								clock-output-names = "l3s_clkctrl";
								compatible = "ti,clkctrl";
								phandle = <0x3b>;
								reg = <0x1c 0x04 0x30 0x08 0x68 0x04 0xf8 0x04>;
							};

							clock@24 {
								#clock-cells = <0x02>;
								clock-output-names = "l3_clkctrl";
								compatible = "ti,clkctrl";
								phandle = <0x07>;
								reg = <0x24 0x0c 0x94 0x10 0xbc 0x04 0xdc 0x08 0xfc 0x08>;
							};

							clock@38 {
								#clock-cells = <0x02>;
								clock-output-names = "l4ls_clkctrl";
								compatible = "ti,clkctrl";
								phandle = <0x38>;
								reg = <0x38 0x2c 0x6c 0x28 0xac 0x0c 0xc0 0x1c 0xec 0x0c 0x10c 0x08 0x130 0x04>;
							};

							clock@e8 {
								#clock-cells = <0x02>;
								clock-output-names = "pruss_ocp_clkctrl";
								compatible = "ti,clkctrl";
								phandle = <0x5a>;
								reg = <0xe8 0x04>;
							};
						};

						clock@400 {
							#address-cells = <0x01>;
							#size-cells = <0x01>;
							clock-output-names = "wkup_cm";
							compatible = "ti,omap4-cm";
							phandle = <0x8b>;
							ranges = <0x00 0x400 0x100>;
							reg = <0x400 0x100>;

							clock@0 {
								#clock-cells = <0x02>;
								clock-output-names = "l4_wkup_clkctrl";
								compatible = "ti,clkctrl";
								phandle = <0x0b>;
								reg = <0x00 0x10 0xb4 0x24>;
							};

							clock@14 {
								#clock-cells = <0x02>;
								clock-output-names = "l3_aon_clkctrl";
								compatible = "ti,clkctrl";
								phandle = <0x08>;
								reg = <0x14 0x04>;
							};

							clock@b0 {
								#clock-cells = <0x02>;
								clock-output-names = "l4_wkup_aon_clkctrl";
								compatible = "ti,clkctrl";
								phandle = <0x0c>;
								reg = <0xb0 0x04>;
							};
						};

						clock@600 {
							#address-cells = <0x01>;
							#size-cells = <0x01>;
							clock-output-names = "mpu_cm";
							compatible = "ti,omap4-cm";
							phandle = <0x8c>;
							ranges = <0x00 0x600 0x100>;
							reg = <0x600 0x100>;

							clock@0 {
								#clock-cells = <0x02>;
								clock-output-names = "mpu_clkctrl";
								compatible = "ti,clkctrl";
								phandle = <0x48>;
								reg = <0x00 0x08>;
							};
						};

						clock@800 {
							#address-cells = <0x01>;
							#size-cells = <0x01>;
							clock-output-names = "l4_rtc_cm";
							compatible = "ti,omap4-cm";
							phandle = <0x8d>;
							ranges = <0x00 0x800 0x100>;
							reg = <0x800 0x100>;

							clock@0 {
								#clock-cells = <0x02>;
								clock-output-names = "l4_rtc_clkctrl";
								compatible = "ti,clkctrl";
								phandle = <0x37>;
								reg = <0x00 0x04>;
							};
						};

						clock@900 {
							#address-cells = <0x01>;
							#size-cells = <0x01>;
							clock-output-names = "gfx_l3_cm";
							compatible = "ti,omap4-cm";
							phandle = <0x8e>;
							ranges = <0x00 0x900 0x100>;
							reg = <0x900 0x100>;

							clock@0 {
								#clock-cells = <0x02>;
								clock-output-names = "gfx_l3_clkctrl";
								compatible = "ti,clkctrl";
								phandle = <0x64>;
								reg = <0x00 0x08>;
							};
						};

						clock@a00 {
							#address-cells = <0x01>;
							#size-cells = <0x01>;
							clock-output-names = "l4_cefuse_cm";
							compatible = "ti,omap4-cm";
							phandle = <0x8f>;
							ranges = <0x00 0xa00 0x100>;
							reg = <0xa00 0x100>;

							clock@0 {
								#clock-cells = <0x02>;
								clock-output-names = "l4_cefuse_clkctrl";
								compatible = "ti,clkctrl";
								phandle = <0x90>;
								reg = <0x00 0x24>;
							};
						};

						clockdomains {
							phandle = <0x89>;
						};

						clocks {
							#address-cells = <0x01>;
							#size-cells = <0x00>;
							phandle = <0x70>;

							clock-clk-24mhz {
								#clock-cells = <0x00>;
								clock-div = <0x08>;
								clock-mult = <0x01>;
								clock-output-names = "clk_24mhz";
								clocks = <0x14>;
								compatible = "fixed-factor-clock";
								phandle = <0x15>;
							};

							clock-clk-32768 {
								#clock-cells = <0x00>;
								clock-frequency = <0x8000>;
								clock-output-names = "clk_32768_ck";
								compatible = "fixed-clock";
								phandle = <0x1c>;
							};

							clock-clk-rc32k {
								#clock-cells = <0x00>;
								clock-frequency = <0x7d00>;
								clock-output-names = "clk_rc32k_ck";
								compatible = "fixed-clock";
								phandle = <0x1b>;
							};

							clock-clkdiv32k {
								#clock-cells = <0x00>;
								clock-div = <0x2dc>;
								clock-mult = <0x01>;
								clock-output-names = "clkdiv32k_ck";
								clocks = <0x15>;
								compatible = "fixed-factor-clock";
								phandle = <0x76>;
							};

							clock-cpsw-125mhz-gclk {
								#clock-cells = <0x00>;
								clock-div = <0x02>;
								clock-mult = <0x01>;
								clock-output-names = "cpsw_125mhz_gclk";
								clocks = <0x1e>;
								compatible = "fixed-factor-clock";
								phandle = <0x52>;
							};

							clock-cpsw-cpts-rft@520 {
								#clock-cells = <0x00>;
								clock-output-names = "cpsw_cpts_rft_clk";
								clocks = <0x1e 0x16>;
								compatible = "ti,mux-clock";
								phandle = <0x53>;
								reg = <0x520>;
							};

							clock-dpll-core-m4-div2 {
								#clock-cells = <0x00>;
								clock-div = <0x02>;
								clock-mult = <0x01>;
								clock-output-names = "dpll_core_m4_div2_ck";
								clocks = <0x16>;
								compatible = "fixed-factor-clock";
								phandle = <0x1d>;
							};

							clock-dpll-core-m4@480 {
								#clock-cells = <0x00>;
								clock-output-names = "dpll_core_m4_ck";
								clocks = <0x0f>;
								compatible = "ti,divider-clock";
								phandle = <0x16>;
								reg = <0x480>;
								ti,index-starts-at-one;
								ti,max-div = <0x1f>;
							};

							clock-dpll-core-m5@484 {
								#clock-cells = <0x00>;
								clock-output-names = "dpll_core_m5_ck";
								clocks = <0x0f>;
								compatible = "ti,divider-clock";
								phandle = <0x1e>;
								reg = <0x484>;
								ti,index-starts-at-one;
								ti,max-div = <0x1f>;
							};

							clock-dpll-core-m6@4d8 {
								#clock-cells = <0x00>;
								clock-output-names = "dpll_core_m6_ck";
								clocks = <0x0f>;
								compatible = "ti,divider-clock";
								phandle = <0x71>;
								reg = <0x4d8>;
								ti,index-starts-at-one;
								ti,max-div = <0x1f>;
							};

							clock-dpll-core-x2 {
								#clock-cells = <0x00>;
								clock-output-names = "dpll_core_x2_ck";
								clocks = <0x0e>;
								compatible = "ti,am3-dpll-x2-clock";
								phandle = <0x0f>;
							};

							clock-dpll-ddr-m2-div2 {
								#clock-cells = <0x00>;
								clock-div = <0x02>;
								clock-mult = <0x01>;
								clock-output-names = "dpll_ddr_m2_div2_ck";
								clocks = <0x11>;
								compatible = "fixed-factor-clock";
								phandle = <0x73>;
							};

							clock-dpll-ddr-m2@4a0 {
								#clock-cells = <0x00>;
								clock-output-names = "dpll_ddr_m2_ck";
								clocks = <0x10>;
								compatible = "ti,divider-clock";
								phandle = <0x11>;
								reg = <0x4a0>;
								ti,index-starts-at-one;
								ti,max-div = <0x1f>;
							};

							clock-dpll-disp-m2@4a4 {
								#clock-cells = <0x00>;
								clock-output-names = "dpll_disp_m2_ck";
								clocks = <0x12>;
								compatible = "ti,divider-clock";
								phandle = <0x18>;
								reg = <0x4a4>;
								ti,index-starts-at-one;
								ti,max-div = <0x1f>;
								ti,set-rate-parent;
							};

							clock-dpll-mpu-m2@4a8 {
								#clock-cells = <0x00>;
								clock-output-names = "dpll_mpu_m2_ck";
								clocks = <0x03>;
								compatible = "ti,divider-clock";
								phandle = <0x72>;
								reg = <0x4a8>;
								ti,index-starts-at-one;
								ti,max-div = <0x1f>;
							};

							clock-dpll-per-m2-div4 {
								#clock-cells = <0x00>;
								clock-div = <0x04>;
								clock-mult = <0x01>;
								clock-output-names = "dpll_per_m2_div4_ck";
								clocks = <0x14>;
								compatible = "fixed-factor-clock";
								phandle = <0x75>;
							};

							clock-dpll-per-m2-div4-wkupdm {
								#clock-cells = <0x00>;
								clock-div = <0x04>;
								clock-mult = <0x01>;
								clock-output-names = "dpll_per_m2_div4_wkupdm_ck";
								clocks = <0x14>;
								compatible = "fixed-factor-clock";
								phandle = <0x74>;
							};

							clock-dpll-per-m2@4ac {
								#clock-cells = <0x00>;
								clock-output-names = "dpll_per_m2_ck";
								clocks = <0x13>;
								compatible = "ti,divider-clock";
								phandle = <0x14>;
								reg = <0x4ac>;
								ti,index-starts-at-one;
								ti,max-div = <0x1f>;
							};

							clock-gpio0-dbclk-mux@53c {
								#clock-cells = <0x00>;
								clock-output-names = "gpio0_dbclk_mux_ck";
								clocks = <0x1b 0x1c 0x19 0x00 0x00>;
								compatible = "ti,mux-clock";
								phandle = <0x85>;
								reg = <0x53c>;
							};

							clock-ieee5000-fck-1@e4 {
								#clock-cells = <0x00>;
								clock-output-names = "ieee5000_fck";
								clocks = <0x1d>;
								compatible = "ti,gate-clock";
								phandle = <0x7e>;
								reg = <0xe4>;
								ti,bit-shift = <0x01>;
							};

							clock-l3-gclk {
								#clock-cells = <0x00>;
								clock-div = <0x01>;
								clock-mult = <0x01>;
								clock-output-names = "l3_gclk";
								clocks = <0x16>;
								compatible = "fixed-factor-clock";
								phandle = <0x17>;
							};

							clock-l3s-gclk {
								#clock-cells = <0x00>;
								clock-div = <0x01>;
								clock-mult = <0x01>;
								clock-output-names = "l3s_gclk";
								clocks = <0x1d>;
								compatible = "fixed-factor-clock";
								phandle = <0x82>;
							};

							clock-l4-rtc-gclk {
								#clock-cells = <0x00>;
								clock-div = <0x02>;
								clock-mult = <0x01>;
								clock-output-names = "l4_rtc_gclk";
								clocks = <0x16>;
								compatible = "fixed-factor-clock";
								phandle = <0x80>;
							};

							clock-l4fw-gclk {
								#clock-cells = <0x00>;
								clock-div = <0x01>;
								clock-mult = <0x01>;
								clock-output-names = "l4fw_gclk";
								clocks = <0x1d>;
								compatible = "fixed-factor-clock";
								phandle = <0x83>;
							};

							clock-l4hs-gclk {
								#clock-cells = <0x00>;
								clock-div = <0x01>;
								clock-mult = <0x01>;
								clock-output-names = "l4hs_gclk";
								clocks = <0x16>;
								compatible = "fixed-factor-clock";
								phandle = <0x81>;
							};

							clock-l4ls-gclk {
								#clock-cells = <0x00>;
								clock-div = <0x01>;
								clock-mult = <0x01>;
								clock-output-names = "l4ls_gclk";
								clocks = <0x1d>;
								compatible = "fixed-factor-clock";
								phandle = <0x31>;
							};

							clock-lcd-gclk@534 {
								#clock-cells = <0x00>;
								clock-output-names = "lcd_gclk";
								clocks = <0x18 0x1e 0x14>;
								compatible = "ti,mux-clock";
								phandle = <0x20>;
								reg = <0x534>;
								ti,set-rate-parent;
							};

							clock-mmc {
								#clock-cells = <0x00>;
								clock-div = <0x02>;
								clock-mult = <0x01>;
								clock-output-names = "mmc_clk";
								clocks = <0x14>;
								compatible = "fixed-factor-clock";
								phandle = <0x86>;
							};

							clock-mmu-fck-1@914 {
								#clock-cells = <0x00>;
								clock-output-names = "mmu_fck";
								clocks = <0x16>;
								compatible = "ti,gate-clock";
								phandle = <0x77>;
								reg = <0x914>;
								ti,bit-shift = <0x01>;
							};

							clock-pruss-ocp-gclk@530 {
								#clock-cells = <0x00>;
								clock-output-names = "pruss_ocp_gclk";
								clocks = <0x17 0x18>;
								compatible = "ti,mux-clock";
								phandle = <0x5b>;
								reg = <0x530>;
							};

							clock-sysclk-div {
								#clock-cells = <0x00>;
								clock-div = <0x01>;
								clock-mult = <0x01>;
								clock-output-names = "sysclk_div_ck";
								clocks = <0x16>;
								compatible = "fixed-factor-clock";
								phandle = <0x84>;
							};

							clock-tclkin {
								#clock-cells = <0x00>;
								clock-frequency = <0xb71b00>;
								clock-output-names = "tclkin_ck";
								compatible = "fixed-clock";
								phandle = <0x1a>;
							};

							clock-timer1-fck@528 {
								#clock-cells = <0x00>;
								clock-output-names = "timer1_fck";
								clocks = <0x0d 0x19 0x00 0x00 0x1a 0x1b 0x1c>;
								compatible = "ti,mux-clock";
								phandle = <0x35>;
								reg = <0x528>;
							};

							clock-timer2-fck@508 {
								#clock-cells = <0x00>;
								clock-output-names = "timer2_fck";
								clocks = <0x1a 0x0d 0x19 0x00 0x00>;
								compatible = "ti,mux-clock";
								phandle = <0x3d>;
								reg = <0x508>;
							};

							clock-timer3-fck@50c {
								#clock-cells = <0x00>;
								clock-output-names = "timer3_fck";
								clocks = <0x1a 0x0d 0x19 0x00 0x00>;
								compatible = "ti,mux-clock";
								phandle = <0x78>;
								reg = <0x50c>;
							};

							clock-timer4-fck@510 {
								#clock-cells = <0x00>;
								clock-output-names = "timer4_fck";
								clocks = <0x1a 0x0d 0x19 0x00 0x00>;
								compatible = "ti,mux-clock";
								phandle = <0x79>;
								reg = <0x510>;
							};

							clock-timer5-fck@518 {
								#clock-cells = <0x00>;
								clock-output-names = "timer5_fck";
								clocks = <0x1a 0x0d 0x19 0x00 0x00>;
								compatible = "ti,mux-clock";
								phandle = <0x7a>;
								reg = <0x518>;
							};

							clock-timer6-fck@51c {
								#clock-cells = <0x00>;
								clock-output-names = "timer6_fck";
								clocks = <0x1a 0x0d 0x19 0x00 0x00>;
								compatible = "ti,mux-clock";
								phandle = <0x7b>;
								reg = <0x51c>;
							};

							clock-timer7-fck@504 {
								#clock-cells = <0x00>;
								clock-output-names = "timer7_fck";
								clocks = <0x1a 0x0d 0x19 0x00 0x00>;
								compatible = "ti,mux-clock";
								phandle = <0x7c>;
								reg = <0x504>;
							};

							clock-usbotg-fck-8@47c {
								#clock-cells = <0x00>;
								clock-output-names = "usbotg_fck";
								clocks = <0x13>;
								compatible = "ti,gate-clock";
								phandle = <0x7d>;
								reg = <0x47c>;
								ti,bit-shift = <0x08>;
							};

							clock-virt-19200000 {
								#clock-cells = <0x00>;
								clock-frequency = <0x124f800>;
								clock-output-names = "virt_19200000_ck";
								compatible = "fixed-clock";
								phandle = <0x2d>;
							};

							clock-virt-24000000 {
								#clock-cells = <0x00>;
								clock-frequency = <0x16e3600>;
								clock-output-names = "virt_24000000_ck";
								compatible = "fixed-clock";
								phandle = <0x2e>;
							};

							clock-virt-25000000 {
								#clock-cells = <0x00>;
								clock-frequency = <0x17d7840>;
								clock-output-names = "virt_25000000_ck";
								compatible = "fixed-clock";
								phandle = <0x2f>;
							};

							clock-virt-26000000 {
								#clock-cells = <0x00>;
								clock-frequency = <0x18cba80>;
								clock-output-names = "virt_26000000_ck";
								compatible = "fixed-clock";
								phandle = <0x30>;
							};

							clock-wdt1-fck@538 {
								#clock-cells = <0x00>;
								clock-output-names = "wdt1_fck";
								clocks = <0x1b 0x19 0x00 0x00>;
								compatible = "ti,mux-clock";
								phandle = <0x7f>;
								reg = <0x538>;
							};

							clock@488 {
								#clock-cells = <0x00>;
								clock-output-names = "dpll_mpu_ck";
								clocks = <0x0d 0x0d>;
								compatible = "ti,am3-dpll-clock";
								phandle = <0x03>;
								reg = <0x488 0x420 0x42c 0x424 0x428>;
							};

							clock@48c {
								#clock-cells = <0x00>;
								clock-output-names = "dpll_per_ck";
								clocks = <0x0d 0x0d>;
								compatible = "ti,am3-dpll-no-gate-j-type-clock";
								phandle = <0x13>;
								reg = <0x48c 0x470 0x49c 0x474 0x478>;
							};

							clock@490 {
								#clock-cells = <0x00>;
								clock-output-names = "dpll_core_ck";
								clocks = <0x0d 0x0d>;
								compatible = "ti,am3-dpll-core-clock";
								phandle = <0x0e>;
								reg = <0x490 0x45c 0x468 0x460 0x464>;
							};

							clock@494 {
								#clock-cells = <0x00>;
								clock-output-names = "dpll_ddr_ck";
								clocks = <0x0d 0x0d>;
								compatible = "ti,am3-dpll-no-gate-clock";
								phandle = <0x10>;
								reg = <0x494 0x434 0x440 0x438 0x43c>;
							};

							clock@498 {
								#clock-cells = <0x00>;
								clock-output-names = "dpll_disp_ck";
								clocks = <0x0d 0x0d>;
								compatible = "ti,am3-dpll-no-gate-clock";
								phandle = <0x12>;
								reg = <0x498 0x448 0x454 0x44c 0x450>;
							};

							clock@52c {
								#address-cells = <0x01>;
								#clock-cells = <0x02>;
								#size-cells = <0x00>;
								compatible = "ti,clksel";
								reg = <0x52c>;

								clock-gfx-fck-div@0 {
									#clock-cells = <0x00>;
									clock-output-names = "gfx_fck_div_ck";
									clocks = <0x1f>;
									compatible = "ti,divider-clock";
									phandle = <0x87>;
									reg = <0x00>;
									ti,max-div = <0x02>;
								};

								clock-gfx-fclk-clksel@1 {
									#clock-cells = <0x00>;
									clock-output-names = "gfx_fclk_clksel_ck";
									clocks = <0x16 0x14>;
									compatible = "ti,mux-clock";
									phandle = <0x1f>;
									reg = <0x01>;
								};
							};

							clock@700 {
								#address-cells = <0x01>;
								#clock-cells = <0x02>;
								#size-cells = <0x00>;
								compatible = "ti,clksel";
								reg = <0x700>;

								clock-clkout2-div@3 {
									#clock-cells = <0x00>;
									clock-output-names = "clkout2_div_ck";
									clocks = <0x21>;
									compatible = "ti,divider-clock";
									phandle = <0x22>;
									reg = <0x03>;
									ti,max-div = <0x08>;
								};

								clock-clkout2@7 {
									#clock-cells = <0x00>;
									clock-output-names = "clkout2_ck";
									clocks = <0x22>;
									compatible = "ti,gate-clock";
									phandle = <0x88>;
									reg = <0x07>;
								};

								clock-sysclkout-pre@0 {
									#clock-cells = <0x00>;
									clock-output-names = "sysclkout_pre_ck";
									clocks = <0x1c 0x17 0x11 0x14 0x20>;
									compatible = "ti,mux-clock";
									phandle = <0x21>;
									reg = <0x00>;
								};
							};
						};

						prm@1000 {
							#power-domain-cells = <0x00>;
							compatible = "ti,am3-prm-inst\0ti,omap-prm-inst";
							phandle = <0x36>;
							reg = <0x1000 0x100>;
						};

						prm@1100 {
							#power-domain-cells = <0x00>;
							#reset-cells = <0x01>;
							compatible = "ti,am3-prm-inst\0ti,omap-prm-inst";
							phandle = <0x65>;
							reg = <0x1100 0x100>;
						};

						prm@1200 {
							#power-domain-cells = <0x00>;
							compatible = "ti,am3-prm-inst\0ti,omap-prm-inst";
							phandle = <0x92>;
							reg = <0x1200 0x100>;
						};

						prm@c00 {
							#power-domain-cells = <0x00>;
							#reset-cells = <0x01>;
							compatible = "ti,am3-prm-inst\0ti,omap-prm-inst";
							phandle = <0x09>;
							reg = <0xc00 0x100>;
						};

						prm@d00 {
							#power-domain-cells = <0x00>;
							#reset-cells = <0x01>;
							compatible = "ti,am3-prm-inst\0ti,omap-prm-inst";
							phandle = <0x0a>;
							reg = <0xd00 0x100>;
						};

						prm@e00 {
							#power-domain-cells = <0x00>;
							compatible = "ti,am3-prm-inst\0ti,omap-prm-inst";
							phandle = <0x47>;
							reg = <0xe00 0x100>;
						};

						prm@f00 {
							#reset-cells = <0x01>;
							compatible = "ti,am3-prm-inst\0ti,omap-prm-inst";
							phandle = <0x91>;
							reg = <0xf00 0x100>;
						};
					};
				};

				target-module@10000 {
					#address-cells = <0x01>;
					#size-cells = <0x01>;
					clock-names = "fck";
					clocks = <0x0b 0x04 0x00>;
					compatible = "ti,sysc-omap4\0ti,sysc";
					ranges = <0x00 0x10000 0x10000 0x10000 0x20000 0x10000>;
					reg = <0x10000 0x04>;
					reg-names = "rev";
					ti,no-idle;

					scm@0 {
						#address-cells = <0x01>;
						#pinctrl-cells = <0x01>;
						#size-cells = <0x01>;
						compatible = "ti,am3-scm\0simple-bus";
						phandle = <0x9f>;
						ranges = <0x00 0x00 0x2000>;
						reg = <0x00 0x2000>;

						clockdomains {
							phandle = <0xaa>;
						};

						control@620 {
							compatible = "ti,am335x-usb-ctrl-module";
							phandle = <0x5f>;
							reg = <0x620 0x10 0x648 0x04>;
							reg-names = "phy_ctrl\0wakeup";
						};

						dma-router@f90 {
							#dma-cells = <0x03>;
							compatible = "ti,am335x-edma-crossbar";
							dma-masters = <0x24>;
							dma-requests = <0x20>;
							phandle = <0xa9>;
							reg = <0xf90 0x40>;
						};

						pinmux@800 {
							#pinctrl-cells = <0x02>;
							compatible = "pinctrl-single";
							phandle = <0x23>;
							pinctrl-single,function-mask = <0x7f>;
							pinctrl-single,register-width = <0x20>;
							reg = <0x800 0x238>;

							cpsw-default-pins {
								phandle = <0x55>;
								pinctrl-single,pins = <0x110 0x30 0x00 0x114 0x00 0x00 0x118 0x30 0x00 0x11c 0x00 0x00 0x120 0x00 0x00 0x124 0x00 0x00 0x128 0x00 0x00 0x12c 0x30 0x00 0x130 0x30 0x00 0x134 0x30 0x00 0x138 0x30 0x00 0x13c 0x30 0x00 0x140 0x30 0x00>;
							};

							cpsw-sleep-pins {
								phandle = <0x56>;
								pinctrl-single,pins = <0x110 0x20 0x07 0x114 0x20 0x07 0x118 0x20 0x07 0x11c 0x20 0x07 0x120 0x20 0x07 0x124 0x20 0x07 0x128 0x20 0x07 0x12c 0x20 0x07 0x130 0x20 0x07 0x134 0x20 0x07 0x138 0x20 0x07 0x13c 0x20 0x07 0x140 0x20 0x07>;
							};

							davinci-mdio-default-pins {
								phandle = <0x58>;
								pinctrl-single,pins = <0x148 0x30 0x00 0x14c 0x10 0x00 0x168 0x10 0x07>;
							};

							davinci-mdio-sleep-pins {
								phandle = <0x59>;
								pinctrl-single,pins = <0x148 0x20 0x07 0x14c 0x20 0x07 0x168 0x20 0x07>;
							};

							emmc-pins {
								phandle = <0x46>;
								pinctrl-single,pins = <0x80 0x30 0x02 0x84 0x30 0x02 0x00 0x30 0x01 0x04 0x30 0x01 0x08 0x30 0x01 0x0c 0x30 0x01 0x10 0x30 0x01 0x14 0x30 0x01 0x18 0x30 0x01 0x1c 0x30 0x01>;
							};

							i2c0-pins {
								phandle = <0x26>;
								pinctrl-single,pins = <0x188 0x30 0x00 0x18c 0x30 0x00>;
							};

							i2c2-pins {
								phandle = <0x41>;
								pinctrl-single,pins = <0x178 0x30 0x03 0x17c 0x30 0x03>;
							};

							mcasp0-pins {
								phandle = <0x3c>;
								pinctrl-single,pins = <0x1ac 0x30 0x00 0x19c 0x00 0x02 0x194 0x10 0x00 0x190 0x00 0x00 0x6c 0x00 0x07>;
							};

							mmc1-pins {
								phandle = <0x3e>;
								pinctrl-single,pins = <0x160 0x28 0x07 0xfc 0x30 0x00 0xf8 0x30 0x00 0xf4 0x30 0x00 0xf0 0x30 0x00 0x104 0x30 0x00 0x100 0x30 0x00>;
							};

							nxp-hdmi-bonelt-off-pins {
								phandle = <0x2a>;
								pinctrl-single,pins = <0x1b0 0x00 0x03>;
							};

							nxp-hdmi-bonelt-pins {
								phandle = <0x29>;
								pinctrl-single,pins = <0x1b0 0x00 0x03 0xa0 0x08 0x00 0xa4 0x08 0x00 0xa8 0x08 0x00 0xac 0x08 0x00 0xb0 0x08 0x00 0xb4 0x08 0x00 0xb8 0x08 0x00 0xbc 0x08 0x00 0xc0 0x08 0x00 0xc4 0x08 0x00 0xc8 0x08 0x00 0xcc 0x08 0x00 0xd0 0x08 0x00 0xd4 0x08 0x00 0xd8 0x08 0x00 0xdc 0x08 0x00 0xe0 0x00 0x00 0xe4 0x00 0x00 0xe8 0x00 0x00 0xec 0x00 0x00>;
							};

							pinmux_comms_can_pins {
								phandle = <0x45>;
								pinctrl-single,pins = <0x184 0x32 0x180 0x12>;
							};

							pinmux_comms_rs485_pins {
								phandle = <0x42>;
								pinctrl-single,pins = <0x74 0x0e 0x70 0x2e>;
							};

							spi0-alt-pins {
								phandle = <0x39>;
								pinctrl-single,pins = <0x150 0x30 0x00 0x154 0x30 0x00 0x158 0x10 0x00 0x15c 0x10 0x00>;
							};

							ssd1306-spi-pins {
								phandle = <0x3a>;
								pinctrl-single,pins = <0x44 0x08 0x07 0x40 0x08 0x07>;
							};

							uart0-pins {
								phandle = <0x25>;
								pinctrl-single,pins = <0x170 0x30 0x00 0x174 0x00 0x00>;
							};

							user-leds-s0-pins {
								phandle = <0x66>;
								pinctrl-single,pins = <0x54 0x00 0x07 0x58 0x10 0x07 0x5c 0x00 0x07 0x60 0x10 0x07>;
							};
						};

						scm_conf@0 {
							#address-cells = <0x01>;
							#size-cells = <0x01>;
							compatible = "syscon\0simple-bus";
							phandle = <0x06>;
							ranges = <0x00 0x00 0x800>;
							reg = <0x00 0x800>;

							clocks {
								#address-cells = <0x01>;
								#size-cells = <0x00>;
								phandle = <0xa0>;

								clock-adc-tsc-fck {
									#clock-cells = <0x00>;
									clock-div = <0x01>;
									clock-mult = <0x01>;
									clock-output-names = "adc_tsc_fck";
									clocks = <0x0d>;
									compatible = "fixed-factor-clock";
									phandle = <0x2c>;
								};

								clock-aes0-fck {
									#clock-cells = <0x00>;
									clock-div = <0x01>;
									clock-mult = <0x01>;
									clock-output-names = "aes0_fck";
									clocks = <0x0d>;
									compatible = "fixed-factor-clock";
									phandle = <0xa6>;
								};

								clock-dcan0-fck {
									#clock-cells = <0x00>;
									clock-div = <0x01>;
									clock-mult = <0x01>;
									clock-output-names = "dcan0_fck";
									clocks = <0x0d>;
									compatible = "fixed-factor-clock";
									phandle = <0x43>;
								};

								clock-dcan1-fck {
									#clock-cells = <0x00>;
									clock-div = <0x01>;
									clock-mult = <0x01>;
									clock-output-names = "dcan1_fck";
									clocks = <0x0d>;
									compatible = "fixed-factor-clock";
									phandle = <0x44>;
								};

								clock-mcasp0-fck {
									#clock-cells = <0x00>;
									clock-div = <0x01>;
									clock-mult = <0x01>;
									clock-output-names = "mcasp0_fck";
									clocks = <0x0d>;
									compatible = "fixed-factor-clock";
									phandle = <0xa1>;
								};

								clock-mcasp1-fck {
									#clock-cells = <0x00>;
									clock-div = <0x01>;
									clock-mult = <0x01>;
									clock-output-names = "mcasp1_fck";
									clocks = <0x0d>;
									compatible = "fixed-factor-clock";
									phandle = <0xa2>;
								};

								clock-rng-fck {
									#clock-cells = <0x00>;
									clock-div = <0x01>;
									clock-mult = <0x01>;
									clock-output-names = "rng_fck";
									clocks = <0x0d>;
									compatible = "fixed-factor-clock";
									phandle = <0xa7>;
								};

								clock-sha0-fck {
									#clock-cells = <0x00>;
									clock-div = <0x01>;
									clock-mult = <0x01>;
									clock-output-names = "sha0_fck";
									clocks = <0x0d>;
									compatible = "fixed-factor-clock";
									phandle = <0xa5>;
								};

								clock-smartreflex0-fck {
									#clock-cells = <0x00>;
									clock-div = <0x01>;
									clock-mult = <0x01>;
									clock-output-names = "smartreflex0_fck";
									clocks = <0x0d>;
									compatible = "fixed-factor-clock";
									phandle = <0xa3>;
								};

								clock-smartreflex1-fck {
									#clock-cells = <0x00>;
									clock-div = <0x01>;
									clock-mult = <0x01>;
									clock-output-names = "smartreflex1_fck";
									clocks = <0x0d>;
									compatible = "fixed-factor-clock";
									phandle = <0xa4>;
								};

								clock-sys-clkin-22@40 {
									#clock-cells = <0x00>;
									clock-output-names = "sys_clkin_ck";
									clocks = <0x2d 0x2e 0x2f 0x30>;
									compatible = "ti,mux-clock";
									phandle = <0x0d>;
									reg = <0x40>;
									ti,bit-shift = <0x16>;
								};

								clock@664 {
									#address-cells = <0x01>;
									#clock-cells = <0x02>;
									#size-cells = <0x00>;
									compatible = "ti,clksel";
									reg = <0x664>;

									clock-ehrpwm0-tbclk@0 {
										#clock-cells = <0x00>;
										clock-output-names = "ehrpwm0_tbclk";
										clocks = <0x31>;
										compatible = "ti,gate-clock";
										phandle = <0x4b>;
										reg = <0x00>;
									};

									clock-ehrpwm1-tbclk@1 {
										#clock-cells = <0x00>;
										clock-output-names = "ehrpwm1_tbclk";
										clocks = <0x31>;
										compatible = "ti,gate-clock";
										phandle = <0x4c>;
										reg = <0x01>;
									};

									clock-ehrpwm2-tbclk@2 {
										#clock-cells = <0x00>;
										clock-output-names = "ehrpwm2_tbclk";
										clocks = <0x31>;
										compatible = "ti,gate-clock";
										phandle = <0x4d>;
										reg = <0x02>;
									};
								};
							};

							phy-gmii-sel {
								#phy-cells = <0x02>;
								compatible = "ti,am3352-phy-gmii-sel";
								phandle = <0x54>;
								reg = <0x650 0x04>;
							};
						};

						wkup_m3_ipc@1324 {
							compatible = "ti,am3352-wkup-m3-ipc";
							firmware-name = "am335x-bone-scale-data.bin";
							interrupts = <0x4e>;
							mboxes = <0x33 0x34>;
							phandle = <0xa8>;
							reg = <0x1324 0x24>;
							ti,rproc = <0x32>;
						};
					};
				};

				target-module@3000 {
					#address-cells = <0x01>;
					#size-cells = <0x01>;
					compatible = "ti,sysc";
					ranges = <0x00 0x3000 0x1000>;
					status = "disabled";
				};

				target-module@31000 {
					#address-cells = <0x01>;
					#size-cells = <0x01>;
					clock-names = "fck\0ick";
					clocks = <0x0b 0xc4 0x00 0x0b 0x0c 0x00>;
					compatible = "ti,sysc-omap2-timer\0ti,sysc";
					phandle = <0xab>;
					ranges = <0x00 0x31000 0x1000>;
					reg = <0x31000 0x04 0x31010 0x04 0x31014 0x04>;
					reg-names = "rev\0sysc\0syss";
					ti,no-idle;
					ti,no-reset-on-init;
					ti,sysc-mask = <0x303>;
					ti,sysc-sidle = <0x00 0x01 0x02>;
					ti,syss-mask = <0x01>;

					timer@0 {
						assigned-clock-parents = <0x0d>;
						assigned-clocks = <0x35>;
						clock-names = "fck";
						clocks = <0x35>;
						compatible = "ti,am335x-timer-1ms";
						interrupts = <0x43>;
						phandle = <0xac>;
						reg = <0x00 0x400>;
						ti,timer-alwon;
					};
				};

				target-module@33000 {
					#address-cells = <0x01>;
					#size-cells = <0x01>;
					compatible = "ti,sysc";
					ranges = <0x00 0x33000 0x1000>;
					status = "disabled";
				};

				target-module@35000 {
					#address-cells = <0x01>;
					#size-cells = <0x01>;
					clock-names = "fck";
					clocks = <0x0b 0xd4 0x00>;
					compatible = "ti,sysc-omap2\0ti,sysc";
					ranges = <0x00 0x35000 0x1000>;
					reg = <0x35000 0x04 0x35010 0x04 0x35014 0x04>;
					reg-names = "rev\0sysc\0syss";
					ti,sysc-mask = <0x22>;
					ti,sysc-sidle = <0x00 0x01 0x02 0x03>;
					ti,syss-mask = <0x01>;

					wdt@0 {
						compatible = "ti,omap3-wdt";
						interrupts = <0x5b>;
						phandle = <0xad>;
						reg = <0x00 0x1000>;
					};
				};

				target-module@37000 {
					#address-cells = <0x01>;
					#size-cells = <0x01>;
					compatible = "ti,sysc";
					ranges = <0x00 0x37000 0x1000>;
					status = "disabled";
				};

				target-module@39000 {
					#address-cells = <0x01>;
					#size-cells = <0x01>;
					compatible = "ti,sysc";
					ranges = <0x00 0x39000 0x1000>;
					status = "disabled";
				};

				target-module@3e000 {
					#address-cells = <0x01>;
					#size-cells = <0x01>;
					clock-names = "fck";
					clocks = <0x37 0x00 0x00>;
					compatible = "ti,sysc-omap4-simple\0ti,sysc";
					power-domains = <0x36>;
					ranges = <0x00 0x3e000 0x1000>;
					reg = <0x3e074 0x04 0x3e078 0x04>;
					reg-names = "rev\0sysc";
					ti,sysc-sidle = <0x00 0x01 0x02 0x03>;

					rtc@0 {
						clock-names = "ext-clk\0int-clk";
						clocks = <0x1c 0x19 0x00 0x00>;
						compatible = "ti,am3352-rtc\0ti,da830-rtc";
						interrupts = <0x4b 0x4c>;
						phandle = <0xae>;
						reg = <0x00 0x1000>;
						system-power-controller;
					};
				};

				target-module@40000 {
					#address-cells = <0x01>;
					#size-cells = <0x01>;
					compatible = "ti,sysc";
					ranges = <0x00 0x40000 0x40000>;
					status = "disabled";
				};

				target-module@5000 {
					#address-cells = <0x01>;
					#size-cells = <0x01>;
					compatible = "ti,sysc";
					ranges = <0x00 0x5000 0x1000>;
					status = "disabled";
				};

				target-module@7000 {
					#address-cells = <0x01>;
					#size-cells = <0x01>;
					clock-names = "fck\0dbclk";
					clocks = <0x0b 0x08 0x00 0x0b 0x08 0x12>;
					compatible = "ti,sysc-omap2\0ti,sysc";
					phandle = <0x93>;
					ranges = <0x00 0x7000 0x1000>;
					reg = <0x7000 0x04 0x7010 0x04 0x7114 0x04>;
					reg-names = "rev\0sysc\0syss";
					ti,sysc-mask = <0x07>;
					ti,sysc-sidle = <0x00 0x01 0x02 0x03>;
					ti,syss-mask = <0x01>;

					gpio@0 {
						#gpio-cells = <0x02>;
						#interrupt-cells = <0x02>;
						compatible = "ti,omap4-gpio";
						gpio-controller;
						gpio-line-names = "[mdio_data]\0[mdio_clk]\0P9_22 [spi0_sclk]\0P9_21 [spi0_d0]\0P9_18 [spi0_d1]\0P9_17 [spi0_cs0]\0[mmc0_cd]\0P9_42A [ecappwm0]\0P8_35 [lcd d12]\0P8_33 [lcd d13]\0P8_31 [lcd d14]\0P8_32 [lcd d15]\0P9_20 [i2c2_sda]\0P9_19 [i2c2_scl]\0P9_26 [uart1_rxd]\0P9_24 [uart1_txd]\0[rmii1_txd3]\0[rmii1_txd2]\0[usb0_drvvbus]\0[hdmi cec]\0P9_41B\0[rmii1_txd1]\0P8_19 [ehrpwm2a]\0P8_13 [ehrpwm2b]\0NC\0NC\0P8_14\0P8_17\0[rmii1_txd0]\0[rmii1_refclk]\0P9_11 [uart4_rxd]\0P9_13 [uart4_txd]";
						gpio-ranges = <0x23 0x00 0x52 0x08 0x23 0x08 0x34 0x04 0x23 0x0c 0x5e 0x04 0x23 0x10 0x47 0x02 0x23 0x12 0x87 0x01 0x23 0x13 0x6c 0x02 0x23 0x15 0x49 0x01 0x23 0x16 0x08 0x02 0x23 0x1a 0x0a 0x02 0x23 0x1c 0x4a 0x01 0x23 0x1d 0x51 0x01 0x23 0x1e 0x1c 0x02>;
						interrupt-controller;
						interrupts = <0x60>;
						phandle = <0x3f>;
						reg = <0x00 0x1000>;
					};
				};

				target-module@9000 {
					#address-cells = <0x01>;
					#size-cells = <0x01>;
					clock-names = "fck";
					clocks = <0x0b 0xb4 0x00>;
					compatible = "ti,sysc-omap2\0ti,sysc";
					ranges = <0x00 0x9000 0x1000>;
					reg = <0x9050 0x04 0x9054 0x04 0x9058 0x04>;
					reg-names = "rev\0sysc\0syss";
					ti,sysc-mask = <0x07>;
					ti,sysc-sidle = <0x00 0x01 0x02 0x03>;

					serial@0 {
						clock-frequency = <0x2dc6c00>;
						compatible = "ti,am3352-uart\0ti,omap3-uart";
						dma-names = "tx\0rx";
						dmas = <0x24 0x1a 0x00 0x24 0x1b 0x00>;
						interrupts = <0x48>;
						phandle = <0x94>;
						pinctrl-0 = <0x25>;
						pinctrl-names = "default";
						reg = <0x00 0x1000>;
						status = "okay";
					};
				};

				target-module@b000 {
					#address-cells = <0x01>;
					#size-cells = <0x01>;
					clock-names = "fck";
					clocks = <0x0b 0xb8 0x00>;
					compatible = "ti,sysc-omap2\0ti,sysc";
					ranges = <0x00 0xb000 0x1000>;
					reg = <0xb000 0x08 0xb010 0x08 0xb090 0x08>;
					reg-names = "rev\0sysc\0syss";
					ti,sysc-mask = <0x307>;
					ti,sysc-sidle = <0x00 0x01 0x02 0x03>;
					ti,syss-mask = <0x01>;

					i2c@0 {
						#address-cells = <0x01>;
						#size-cells = <0x00>;
						clock-frequency = <0x61a80>;
						compatible = "ti,omap4-i2c";
						interrupts = <0x46>;
						phandle = <0x95>;
						pinctrl-0 = <0x26>;
						pinctrl-names = "default";
						reg = <0x00 0x1000>;
						status = "okay";
						symlink = "bone/i2c/0";

						eeprom@50 {
							compatible = "atmel,24c32";
							phandle = <0x9b>;
							reg = <0x50>;
							vcc-supply = <0x27>;

							nvmem-layout {
								#address-cells = <0x01>;
								#size-cells = <0x01>;
								compatible = "fixed-layout";

								baseboard_data@0 {
									phandle = <0x9c>;
									reg = <0x00 0x100>;
								};
							};
						};

						pmic@24 {
							#interrupt-cells = <0x01>;
							compatible = "ti,tps65217";
							interrupt-controller;
							interrupt-parent = <0x01>;
							interrupts = <0x07>;
							phandle = <0x62>;
							reg = <0x24>;
							ti,pmic-shutdown-controller;

							charger {
								compatible = "ti,tps65217-charger";
								interrupt-names = "USB\0AC";
								interrupts = <0x00 0x01>;
								status = "okay";
							};

							pwrbutton {
								compatible = "ti,tps65217-pwrbutton";
								interrupts = <0x02>;
								status = "okay";
							};

							regulators {
								#address-cells = <0x01>;
								#size-cells = <0x00>;

								regulator@0 {
									phandle = <0x96>;
									reg = <0x00>;
									regulator-always-on;
									regulator-compatible = "dcdc1";
									regulator-name = "vdds_dpr";
								};

								regulator@1 {
									phandle = <0x05>;
									reg = <0x01>;
									regulator-always-on;
									regulator-boot-on;
									regulator-compatible = "dcdc2";
									regulator-max-microvolt = <0x149f4c>;
									regulator-min-microvolt = <0xe1d48>;
									regulator-name = "vdd_mpu";
								};

								regulator@2 {
									phandle = <0x97>;
									reg = <0x02>;
									regulator-always-on;
									regulator-boot-on;
									regulator-compatible = "dcdc3";
									regulator-max-microvolt = <0x118c30>;
									regulator-min-microvolt = <0xe1d48>;
									regulator-name = "vdd_core";
								};

								regulator@3 {
									phandle = <0x98>;
									reg = <0x03>;
									regulator-always-on;
									regulator-compatible = "ldo1";
									regulator-name = "vio,vrtc,vdds";
								};

								regulator@4 {
									phandle = <0x99>;
									reg = <0x04>;
									regulator-always-on;
									regulator-compatible = "ldo2";
									regulator-name = "vdd_3v3aux";
								};

								regulator@5 {
									phandle = <0x9a>;
									reg = <0x05>;
									regulator-always-on;
									regulator-compatible = "ldo3";
									regulator-max-microvolt = <0x1b7740>;
									regulator-min-microvolt = <0x1b7740>;
									regulator-name = "vdd_1v8";
								};

								regulator@6 {
									phandle = <0x27>;
									reg = <0x06>;
									regulator-always-on;
									regulator-compatible = "ldo4";
									regulator-name = "vdd_3v3a";
								};
							};
						};

						tda19988@70 {
							#sound-dai-cells = <0x00>;
							audio-ports = <0x02 0x03>;
							compatible = "nxp,tda998x";
							interrupts-extended = <0x28 0x19 0x08>;
							nxp,calib-gpios = <0x28 0x19 0x00>;
							phandle = <0x6b>;
							pinctrl-0 = <0x29>;
							pinctrl-1 = <0x2a>;
							pinctrl-names = "default\0off";
							reg = <0x70>;

							ports {
								#address-cells = <0x01>;
								#size-cells = <0x00>;

								port@0 {
									reg = <0x00>;

									endpoint {
										phandle = <0x4f>;
										remote-endpoint = <0x2b>;
									};
								};
							};
						};
					};
				};

				target-module@d000 {
					#address-cells = <0x01>;
					#size-cells = <0x01>;
					clock-names = "fck";
					clocks = <0x0b 0xbc 0x00>;
					compatible = "ti,sysc-omap4\0ti,sysc";
					ranges = <0x00 0xd000 0x1000 0x1000 0xe000 0x1000>;
					reg = <0xd000 0x04 0xd010 0x04>;
					reg-names = "rev\0sysc";
					ti,sysc-sidle = <0x00 0x01 0x02 0x03>;

					tscadc@0 {
						clock-names = "fck";
						clocks = <0x2c>;
						compatible = "ti,am3359-tscadc";
						dma-names = "fifo0\0fifo1";
						dmas = <0x24 0x35 0x00 0x24 0x39 0x00>;
						interrupts = <0x10>;
						phandle = <0x9d>;
						reg = <0x00 0x1000>;
						status = "okay";

						adc {
							#io-channel-cells = <0x01>;
							compatible = "ti,am3359-adc";
							phandle = <0x9e>;
							ti,adc-channels = <0x00 0x01 0x02 0x03 0x04 0x05 0x06 0x07>;
							ti,chan-step-avg = <0x10 0x10 0x10 0x10 0x10 0x10 0x10 0x10>;
							ti,chan-step-opendelay = <0x98 0x98 0x98 0x98 0x98 0x98 0x98 0x98>;
							ti,chan-step-sampledelay = <0x00 0x00 0x00 0x00 0x00 0x00 0x00 0x00>;
						};

						tsc {
							compatible = "ti,am3359-tsc";
						};
					};
				};
			};
		};

		interconnect@47c00000 {
			#address-cells = <0x01>;
			#size-cells = <0x01>;
			compatible = "ti,am33xx-l4-fw\0simple-bus";
			phandle = <0xe0>;
			ranges = <0x00 0x47c00000 0x1000000>;
			reg = <0x47c00000 0x800 0x47c00800 0x800 0x47c01000 0x400>;
			reg-names = "ap\0la\0ia0";

			segment@0 {
				#address-cells = <0x01>;
				#size-cells = <0x01>;
				compatible = "simple-bus";
				ranges = <0x00 0x00 0x800 0x800 0x800 0x800 0x1000 0x1000 0x400 0xc000 0xc000 0x1000 0xd000 0xd000 0x1000 0xe000 0xe000 0x1000 0xf000 0xf000 0x1000 0x10000 0x10000 0x1000 0x11000 0x11000 0x1000 0x1a000 0x1a000 0x1000 0x1b000 0x1b000 0x1000 0x24000 0x24000 0x1000 0x25000 0x25000 0x1000 0x26000 0x26000 0x1000 0x27000 0x27000 0x1000 0x30000 0x30000 0x1000 0x31000 0x31000 0x1000 0x38000 0x38000 0x1000 0x39000 0x39000 0x1000 0x3a000 0x3a000 0x1000 0x3b000 0x3b000 0x1000 0x3e000 0x3e000 0x1000 0x3f000 0x3f000 0x1000 0x3c000 0x3c000 0x1000 0x40000 0x40000 0x1000 0x46000 0x46000 0x1000 0x47000 0x47000 0x1000 0x44000 0x44000 0x1000 0x45000 0x45000 0x1000 0x28000 0x28000 0x1000 0x29000 0x29000 0x1000 0x32000 0x32000 0x1000 0x33000 0x33000 0x1000 0x3d000 0x3d000 0x1000 0x41000 0x41000 0x1000 0x42000 0x42000 0x1000 0x43000 0x43000 0x1000 0x14000 0x14000 0x1000 0x15000 0x15000 0x1000>;

				target-module@10000 {
					#address-cells = <0x01>;
					#size-cells = <0x01>;
					compatible = "ti,sysc";
					ranges = <0x00 0x10000 0x1000>;
					status = "disabled";
				};

				target-module@14000 {
					#address-cells = <0x01>;
					#size-cells = <0x01>;
					compatible = "ti,sysc";
					ranges = <0x00 0x14000 0x1000>;
					status = "disabled";
				};

				target-module@1a000 {
					#address-cells = <0x01>;
					#size-cells = <0x01>;
					compatible = "ti,sysc";
					ranges = <0x00 0x1a000 0x1000>;
					status = "disabled";
				};

				target-module@24000 {
					#address-cells = <0x01>;
					#size-cells = <0x01>;
					compatible = "ti,sysc";
					ranges = <0x00 0x24000 0x1000>;
					status = "disabled";
				};

				target-module@26000 {
					#address-cells = <0x01>;
					#size-cells = <0x01>;
					compatible = "ti,sysc";
					ranges = <0x00 0x26000 0x1000>;
					status = "disabled";
				};

				target-module@28000 {
					#address-cells = <0x01>;
					#size-cells = <0x01>;
					compatible = "ti,sysc";
					ranges = <0x00 0x28000 0x1000>;
					status = "disabled";
				};

				target-module@30000 {
					#address-cells = <0x01>;
					#size-cells = <0x01>;
					compatible = "ti,sysc";
					ranges = <0x00 0x30000 0x1000>;
					status = "disabled";
				};

				target-module@32000 {
					#address-cells = <0x01>;
					#size-cells = <0x01>;
					compatible = "ti,sysc";
					ranges = <0x00 0x32000 0x1000>;
					status = "disabled";
				};

				target-module@38000 {
					#address-cells = <0x01>;
					#size-cells = <0x01>;
					compatible = "ti,sysc";
					ranges = <0x00 0x38000 0x1000>;
					status = "disabled";
				};

				target-module@3a000 {
					#address-cells = <0x01>;
					#size-cells = <0x01>;
					compatible = "ti,sysc";
					ranges = <0x00 0x3a000 0x1000>;
					status = "disabled";
				};

				target-module@3c000 {
					#address-cells = <0x01>;
					#size-cells = <0x01>;
					compatible = "ti,sysc";
					ranges = <0x00 0x3c000 0x1000>;
					status = "disabled";
				};

				target-module@3e000 {
					#address-cells = <0x01>;
					#size-cells = <0x01>;
					compatible = "ti,sysc";
					ranges = <0x00 0x3e000 0x1000>;
					status = "disabled";
				};

				target-module@40000 {
					#address-cells = <0x01>;
					#size-cells = <0x01>;
					compatible = "ti,sysc";
					ranges = <0x00 0x40000 0x1000>;
					status = "disabled";
				};

				target-module@42000 {
					#address-cells = <0x01>;
					#size-cells = <0x01>;
					compatible = "ti,sysc";
					ranges = <0x00 0x42000 0x1000>;
					status = "disabled";
				};

				target-module@44000 {
					#address-cells = <0x01>;
					#size-cells = <0x01>;
					compatible = "ti,sysc";
					ranges = <0x00 0x44000 0x1000>;
					status = "disabled";
				};

				target-module@46000 {
					#address-cells = <0x01>;
					#size-cells = <0x01>;
					compatible = "ti,sysc";
					ranges = <0x00 0x46000 0x1000>;
					status = "disabled";
				};

				target-module@c000 {
					#address-cells = <0x01>;
					#size-cells = <0x01>;
					compatible = "ti,sysc";
					ranges = <0x00 0xc000 0x1000>;
					status = "disabled";
				};

				target-module@e000 {
					#address-cells = <0x01>;
					#size-cells = <0x01>;
					compatible = "ti,sysc";
					ranges = <0x00 0xe000 0x1000>;
					status = "disabled";
				};
			};
		};

		interconnect@48000000 {
			#address-cells = <0x01>;
			#size-cells = <0x01>;
			clock-names = "fck";
			clocks = <0x38 0x28 0x00>;
			compatible = "ti,am33xx-l4-per\0simple-pm-bus";
			phandle = <0xaf>;
			power-domains = <0x09>;
			ranges = <0x00 0x48000000 0x100000 0x100000 0x48100000 0x100000 0x200000 0x48200000 0x100000 0x300000 0x48300000 0x100000 0x46000000 0x46000000 0x400000 0x46400000 0x46400000 0x400000>;
			reg = <0x48000000 0x800 0x48000800 0x800 0x48001000 0x400 0x48001400 0x400 0x48001800 0x400 0x48001c00 0x400>;
			reg-names = "ap\0la\0ia0\0ia1\0ia2\0ia3";

			segment@0 {
				#address-cells = <0x01>;
				#size-cells = <0x01>;
				compatible = "simple-pm-bus";
				ranges = <0x00 0x00 0x800 0x800 0x800 0x800 0x1000 0x1000 0x400 0x1400 0x1400 0x400 0x1800 0x1800 0x400 0x1c00 0x1c00 0x400 0x8000 0x8000 0x1000 0x9000 0x9000 0x1000 0x16000 0x16000 0x1000 0x17000 0x17000 0x1000 0x22000 0x22000 0x1000 0x23000 0x23000 0x1000 0x24000 0x24000 0x1000 0x25000 0x25000 0x1000 0x2a000 0x2a000 0x1000 0x2b000 0x2b000 0x1000 0x38000 0x38000 0x2000 0x3a000 0x3a000 0x1000 0x14000 0x14000 0x1000 0x15000 0x15000 0x1000 0x3c000 0x3c000 0x2000 0x3e000 0x3e000 0x1000 0x40000 0x40000 0x1000 0x41000 0x41000 0x1000 0x42000 0x42000 0x1000 0x43000 0x43000 0x1000 0x44000 0x44000 0x1000 0x45000 0x45000 0x1000 0x46000 0x46000 0x1000 0x47000 0x47000 0x1000 0x48000 0x48000 0x1000 0x49000 0x49000 0x1000 0x4c000 0x4c000 0x1000 0x4d000 0x4d000 0x1000 0x50000 0x50000 0x2000 0x52000 0x52000 0x1000 0x60000 0x60000 0x1000 0x61000 0x61000 0x1000 0x80000 0x80000 0x10000 0x90000 0x90000 0x1000 0xa0000 0xa0000 0x10000 0xb0000 0xb0000 0x1000 0x30000 0x30000 0x1000 0x31000 0x31000 0x1000 0x4a000 0x4a000 0x1000 0x4b000 0x4b000 0x1000 0xc8000 0xc8000 0x1000 0xc9000 0xc9000 0x1000 0xcc000 0xcc000 0x1000 0xcd000 0xcd000 0x1000 0xca000 0xca000 0x1000 0xcb000 0xcb000 0x1000 0x46000000 0x46000000 0x400000 0x46400000 0x46400000 0x400000>;

				target-module@14000 {
					#address-cells = <0x01>;
					#size-cells = <0x01>;
					compatible = "ti,sysc";
					ranges = <0x00 0x14000 0x1000>;
					status = "disabled";
				};

				target-module@16000 {
					#address-cells = <0x01>;
					#size-cells = <0x01>;
					compatible = "ti,sysc";
					ranges = <0x00 0x16000 0x1000>;
					status = "disabled";
				};

				target-module@22000 {
					#address-cells = <0x01>;
					#size-cells = <0x01>;
					clock-names = "fck";
					clocks = <0x38 0x34 0x00>;
					compatible = "ti,sysc-omap2\0ti,sysc";
					ranges = <0x00 0x22000 0x1000>;
					reg = <0x22050 0x04 0x22054 0x04 0x22058 0x04>;
					reg-names = "rev\0sysc\0syss";
					ti,sysc-mask = <0x07>;
					ti,sysc-sidle = <0x00 0x01 0x02 0x03>;

					serial@0 {
						clock-frequency = <0x2dc6c00>;
						compatible = "ti,am3352-uart\0ti,omap3-uart";
						dma-names = "tx\0rx";
						dmas = <0x24 0x1c 0x00 0x24 0x1d 0x00>;
						interrupts = <0x49>;
						phandle = <0xb0>;
						reg = <0x00 0x1000>;
						status = "disabled";
					};
				};

				target-module@24000 {
					#address-cells = <0x01>;
					#size-cells = <0x01>;
					clock-names = "fck";
					clocks = <0x38 0x38 0x00>;
					compatible = "ti,sysc-omap2\0ti,sysc";
					ranges = <0x00 0x24000 0x1000>;
					reg = <0x24050 0x04 0x24054 0x04 0x24058 0x04>;
					reg-names = "rev\0sysc\0syss";
					ti,sysc-mask = <0x07>;
					ti,sysc-sidle = <0x00 0x01 0x02 0x03>;

					serial@0 {
						clock-frequency = <0x2dc6c00>;
						compatible = "ti,am3352-uart\0ti,omap3-uart";
						dma-names = "tx\0rx";
						dmas = <0x24 0x1e 0x00 0x24 0x1f 0x00>;
						interrupts = <0x4a>;
						phandle = <0xb1>;
						reg = <0x00 0x1000>;
						status = "disabled";
					};
				};

				target-module@2a000 {
					#address-cells = <0x01>;
					#size-cells = <0x01>;
					clock-names = "fck";
					clocks = <0x38 0x10 0x00>;
					compatible = "ti,sysc-omap2\0ti,sysc";
					ranges = <0x00 0x2a000 0x1000>;
					reg = <0x2a000 0x08 0x2a010 0x08 0x2a090 0x08>;
					reg-names = "rev\0sysc\0syss";
					ti,sysc-mask = <0x307>;
					ti,sysc-sidle = <0x00 0x01 0x02 0x03>;
					ti,syss-mask = <0x01>;

					i2c@0 {
						#address-cells = <0x01>;
						#size-cells = <0x00>;
						compatible = "ti,omap4-i2c";
						interrupts = <0x47>;
						phandle = <0xb2>;
						reg = <0x00 0x1000>;
						status = "disabled";
					};
				};

				target-module@30000 {
					#address-cells = <0x01>;
					#size-cells = <0x01>;
					clock-names = "fck";
					clocks = <0x38 0x14 0x00>;
					compatible = "ti,sysc-omap2\0ti,sysc";
					ranges = <0x00 0x30000 0x1000>;
					reg = <0x30000 0x04 0x30110 0x04 0x30114 0x04>;
					reg-names = "rev\0sysc\0syss";
					ti,sysc-mask = <0x303>;
					ti,sysc-sidle = <0x00 0x01 0x02>;
					ti,syss-mask = <0x01>;

					spi@0 {
						#address-cells = <0x01>;
						#size-cells = <0x00>;
						compatible = "ti,omap4-mcspi";
						dma-names = "tx0\0rx0\0tx1\0rx1";
						dmas = <0x24 0x10 0x00 0x24 0x11 0x00 0x24 0x12 0x00 0x24 0x13 0x00>;
						interrupts = <0x41>;
						phandle = <0xb3>;
						pinctrl-0 = <0x39 0x3a>;
						pinctrl-names = "default";
						reg = <0x00 0x400>;
						status = "okay";
						ti,spi-num-cs = <0x02>;

						ssd1306@0 {
							compatible = "solomon,ssd1306";
							dc-gpios = <0x28 0x10 0x00>;
							label = "SSD1306";
							reg = <0x00>;
							reset-gpios = <0x28 0x11 0x00>;
							spi-max-frequency = <0x7a1200>;
						};
					};
				};

				target-module@38000 {
					#address-cells = <0x01>;
					#size-cells = <0x01>;
					clock-names = "fck";
					clocks = <0x3b 0x18 0x00>;
					compatible = "ti,sysc-omap4-simple\0ti,sysc";
					ranges = <0x00 0x38000 0x2000 0x46000000 0x46000000 0x400000>;
					reg = <0x38000 0x04 0x38004 0x04>;
					reg-names = "rev\0sysc";
					ti,sysc-sidle = <0x00 0x01 0x02>;

					mcasp@0 {
						#sound-dai-cells = <0x00>;
						compatible = "ti,am33xx-mcasp-audio";
						dma-names = "tx\0rx";
						dmas = <0x24 0x08 0x02 0x24 0x09 0x02>;
						interrupt-names = "tx\0rx";
						interrupts = <0x50 0x51>;
						op-mode = <0x00>;
						phandle = <0x69>;
						pinctrl-0 = <0x3c>;
						pinctrl-names = "default";
						reg = <0x00 0x2000 0x46000000 0x400000>;
						reg-names = "mpu\0dat";
						rx-num-evt = <0x20>;
						serial-dir = <0x00 0x00 0x01 0x00>;
						status = "okay";
						tdm-slots = <0x02>;
						tx-num-evt = <0x20>;
					};
				};

				target-module@3c000 {
					#address-cells = <0x01>;
					#size-cells = <0x01>;
					clock-names = "fck";
					clocks = <0x3b 0x4c 0x00>;
					compatible = "ti,sysc-omap4-simple\0ti,sysc";
					ranges = <0x00 0x3c000 0x2000 0x46400000 0x46400000 0x400000>;
					reg = <0x3c000 0x04 0x3c004 0x04>;
					reg-names = "rev\0sysc";
					ti,sysc-sidle = <0x00 0x01 0x02>;

					mcasp@0 {
						compatible = "ti,am33xx-mcasp-audio";
						dma-names = "tx\0rx";
						dmas = <0x24 0x0a 0x02 0x24 0x0b 0x02>;
						interrupt-names = "tx\0rx";
						interrupts = <0x52 0x53>;
						phandle = <0xb4>;
						reg = <0x00 0x2000 0x46400000 0x400000>;
						reg-names = "mpu\0dat";
						status = "disabled";
					};
				};

				target-module@40000 {
					#address-cells = <0x01>;
					#size-cells = <0x01>;
					clock-names = "fck\0ick";
					clocks = <0x38 0x48 0x00 0x38 0x28 0x00>;
					compatible = "ti,sysc-omap4-timer\0ti,sysc";
					phandle = <0xb5>;
					ranges = <0x00 0x40000 0x1000>;
					reg = <0x40000 0x04 0x40010 0x04 0x40014 0x04>;
					reg-names = "rev\0sysc\0syss";
					ti,no-idle;
					ti,no-reset-on-init;
					ti,sysc-mask = <0x01>;
					ti,sysc-sidle = <0x00 0x01 0x02 0x03>;

					timer@0 {
						assigned-clock-parents = <0x0d>;
						assigned-clocks = <0x3d>;
						clock-names = "fck";
						clocks = <0x3d>;
						compatible = "ti,am335x-timer";
						interrupts = <0x44>;
						phandle = <0xb6>;
						reg = <0x00 0x400>;
					};
				};

				target-module@42000 {
					#address-cells = <0x01>;
					#size-cells = <0x01>;
					clock-names = "fck";
					clocks = <0x38 0x4c 0x00>;
					compatible = "ti,sysc-omap4-timer\0ti,sysc";
					ranges = <0x00 0x42000 0x1000>;
					reg = <0x42000 0x04 0x42010 0x04 0x42014 0x04>;
					reg-names = "rev\0sysc\0syss";
					ti,sysc-mask = <0x01>;
					ti,sysc-sidle = <0x00 0x01 0x02 0x03>;

					timer@0 {
						compatible = "ti,am335x-timer";
						interrupts = <0x45>;
						phandle = <0xb7>;
						reg = <0x00 0x400>;
					};
				};

				target-module@44000 {
					#address-cells = <0x01>;
					#size-cells = <0x01>;
					clock-names = "fck";
					clocks = <0x38 0x50 0x00>;
					compatible = "ti,sysc-omap4-timer\0ti,sysc";
					ranges = <0x00 0x44000 0x1000>;
					reg = <0x44000 0x04 0x44010 0x04 0x44014 0x04>;
					reg-names = "rev\0sysc\0syss";
					ti,sysc-mask = <0x01>;
					ti,sysc-sidle = <0x00 0x01 0x02 0x03>;

					timer@0 {
						compatible = "ti,am335x-timer";
						interrupts = <0x5c>;
						phandle = <0xb8>;
						reg = <0x00 0x400>;
						ti,timer-pwm;
					};
				};

				target-module@46000 {
					#address-cells = <0x01>;
					#size-cells = <0x01>;
					clock-names = "fck";
					clocks = <0x38 0xb4 0x00>;
					compatible = "ti,sysc-omap4-timer\0ti,sysc";
					ranges = <0x00 0x46000 0x1000>;
					reg = <0x46000 0x04 0x46010 0x04 0x46014 0x04>;
					reg-names = "rev\0sysc\0syss";
					ti,sysc-mask = <0x01>;
					ti,sysc-sidle = <0x00 0x01 0x02 0x03>;

					timer@0 {
						compatible = "ti,am335x-timer";
						interrupts = <0x5d>;
						phandle = <0xb9>;
						reg = <0x00 0x400>;
						ti,timer-pwm;
					};
				};

				target-module@48000 {
					#address-cells = <0x01>;
					#size-cells = <0x01>;
					clock-names = "fck";
					clocks = <0x38 0xb8 0x00>;
					compatible = "ti,sysc-omap4-timer\0ti,sysc";
					ranges = <0x00 0x48000 0x1000>;
					reg = <0x48000 0x04 0x48010 0x04 0x48014 0x04>;
					reg-names = "rev\0sysc\0syss";
					ti,sysc-mask = <0x01>;
					ti,sysc-sidle = <0x00 0x01 0x02 0x03>;

					timer@0 {
						compatible = "ti,am335x-timer";
						interrupts = <0x5e>;
						phandle = <0xba>;
						reg = <0x00 0x400>;
						ti,timer-pwm;
					};
				};

				target-module@4a000 {
					#address-cells = <0x01>;
					#size-cells = <0x01>;
					clock-names = "fck";
					clocks = <0x38 0x44 0x00>;
					compatible = "ti,sysc-omap4-timer\0ti,sysc";
					ranges = <0x00 0x4a000 0x1000>;
					reg = <0x4a000 0x04 0x4a010 0x04 0x4a014 0x04>;
					reg-names = "rev\0sysc\0syss";
					ti,sysc-mask = <0x01>;
					ti,sysc-sidle = <0x00 0x01 0x02 0x03>;

					timer@0 {
						compatible = "ti,am335x-timer";
						interrupts = <0x5f>;
						phandle = <0xbb>;
						reg = <0x00 0x400>;
						ti,timer-pwm;
					};
				};

				target-module@4c000 {
					#address-cells = <0x01>;
					#size-cells = <0x01>;
					clock-names = "fck\0dbclk";
					clocks = <0x38 0x74 0x00 0x38 0x74 0x12>;
					compatible = "ti,sysc-omap2\0ti,sysc";
					ranges = <0x00 0x4c000 0x1000>;
					reg = <0x4c000 0x04 0x4c010 0x04 0x4c114 0x04>;
					reg-names = "rev\0sysc\0syss";
					ti,sysc-mask = <0x07>;
					ti,sysc-sidle = <0x00 0x01 0x02 0x03>;
					ti,syss-mask = <0x01>;

					gpio@0 {
						#gpio-cells = <0x02>;
						#interrupt-cells = <0x02>;
						compatible = "ti,omap4-gpio";
						gpio-controller;
						gpio-line-names = "P8_25 [mmc1_dat0]\0[mmc1_dat1]\0P8_5 [mmc1_dat2]\0P8_6 [mmc1_dat3]\0P8_23 [mmc1_dat4]\0P8_22 [mmc1_dat5]\0P8_3 [mmc1_dat6]\0P8_4 [mmc1_dat7]\0NC\0NC\0NC\0NC\0P8_12\0P8_11\0P8_16\0P8_15\0P9_15A\0P9_23\0P9_14 [ehrpwm1a]\0P9_16 [ehrpwm1b]\0[emmc rst]\0[usr0 led]\0[usr1 led]\0[usr2 led]\0[usr3 led]\0[hdmi irq]\0[usb vbus oc]\0[hdmi audio]\0P9_12\0P8_26\0P8_21 [emmc]\0P8_20 [emmc]";
						gpio-ranges = <0x23 0x00 0x00 0x08 0x23 0x08 0x5a 0x04 0x23 0x0c 0x0c 0x10 0x23 0x1c 0x1e 0x04>;
						interrupt-controller;
						interrupts = <0x62>;
						phandle = <0x28>;
						reg = <0x00 0x1000>;
					};
				};

				target-module@50000 {
					#address-cells = <0x01>;
					#size-cells = <0x01>;
					compatible = "ti,sysc";
					ranges = <0x00 0x50000 0x2000>;
					status = "disabled";
				};

				target-module@60000 {
					#address-cells = <0x01>;
					#size-cells = <0x01>;
					clock-names = "fck";
					clocks = <0x38 0x04 0x00>;
					compatible = "ti,sysc-omap2\0ti,sysc";
					ranges = <0x00 0x60000 0x1000>;
					reg = <0x602fc 0x04 0x60110 0x04 0x60114 0x04>;
					reg-names = "rev\0sysc\0syss";
					ti,sysc-mask = <0x307>;
					ti,sysc-sidle = <0x00 0x01 0x02>;
					ti,syss-mask = <0x01>;

					mmc@0 {
						bus-width = <0x04>;
						cd-gpios = <0x3f 0x06 0x01>;
						compatible = "ti,am335-sdhci";
						dma-names = "tx\0rx";
						dmas = <0x24 0x18 0x00 0x24 0x19 0x00>;
						interrupts = <0x40>;
						phandle = <0xbc>;
						pinctrl-0 = <0x3e>;
						pinctrl-names = "default";
						reg = <0x00 0x1000>;
						status = "okay";
						ti,needs-special-reset;
						vmmc-supply = <0x40>;
					};
				};

				target-module@8000 {
					#address-cells = <0x01>;
					#size-cells = <0x01>;
					compatible = "ti,sysc";
					ranges = <0x00 0x8000 0x1000>;
					status = "disabled";
				};

				target-module@80000 {
					#address-cells = <0x01>;
					#size-cells = <0x01>;
					clock-names = "fck";
					clocks = <0x38 0x08 0x00>;
					compatible = "ti,sysc-omap2\0ti,sysc";
					ranges = <0x00 0x80000 0x10000>;
					reg = <0x80000 0x04 0x80010 0x04 0x80014 0x04>;
					reg-names = "rev\0sysc\0syss";
					ti,sysc-mask = <0x303>;
					ti,sysc-sidle = <0x00 0x01 0x02>;
					ti,syss-mask = <0x01>;

					elm@0 {
						compatible = "ti,am3352-elm";
						interrupts = <0x04>;
						phandle = <0xbd>;
						reg = <0x00 0x2000>;
						status = "disabled";
					};
				};

				target-module@a0000 {
					#address-cells = <0x01>;
					#size-cells = <0x01>;
					compatible = "ti,sysc";
					ranges = <0x00 0xa0000 0x10000>;
					status = "disabled";
				};

				target-module@c8000 {
					#address-cells = <0x01>;
					#size-cells = <0x01>;
					clock-names = "fck";
					clocks = <0x38 0xd8 0x00>;
					compatible = "ti,sysc-omap4\0ti,sysc";
					ranges = <0x00 0xc8000 0x1000>;
					reg = <0xc8000 0x04 0xc8010 0x04>;
					reg-names = "rev\0sysc";
					ti,sysc-mask = <0x01>;
					ti,sysc-sidle = <0x00 0x01 0x02>;

					mailbox@0 {
						#mbox-cells = <0x01>;
						compatible = "ti,omap4-mailbox";
						interrupts = <0x4d>;
						phandle = <0x33>;
						reg = <0x00 0x200>;
						ti,mbox-num-fifos = <0x08>;
						ti,mbox-num-users = <0x04>;

						mbox-wkup-m3 {
							phandle = <0x34>;
							ti,mbox-rx = <0x00 0x00 0x03>;
							ti,mbox-send-noirq;
							ti,mbox-tx = <0x00 0x00 0x00>;
						};
					};
				};

				target-module@ca000 {
					#address-cells = <0x01>;
					#size-cells = <0x01>;
					clock-names = "fck";
					clocks = <0x38 0xd4 0x00>;
					compatible = "ti,sysc-omap2\0ti,sysc";
					ranges = <0x00 0xca000 0x1000>;
					reg = <0xca000 0x04 0xca010 0x04 0xca014 0x04>;
					reg-names = "rev\0sysc\0syss";
					ti,sysc-mask = <0x307>;
					ti,sysc-sidle = <0x00 0x01 0x02>;
					ti,syss-mask = <0x01>;

					spinlock@0 {
						#hwlock-cells = <0x01>;
						compatible = "ti,omap4-hwspinlock";
						phandle = <0xbe>;
						reg = <0x00 0x1000>;
					};
				};

				target-module@cc000 {
					#address-cells = <0x01>;
					#size-cells = <0x01>;
					compatible = "ti,sysc";
					ranges = <0x00 0xcc000 0x1000>;
					status = "disabled";
				};
			};

			segment@100000 {
				#address-cells = <0x01>;
				#size-cells = <0x01>;
				compatible = "simple-pm-bus";
				ranges = <0x8c000 0x18c000 0x1000 0x8d000 0x18d000 0x1000 0x8e000 0x18e000 0x1000 0x8f000 0x18f000 0x1000 0x9c000 0x19c000 0x1000 0x9d000 0x19d000 0x1000 0xa6000 0x1a6000 0x1000 0xa7000 0x1a7000 0x1000 0xa8000 0x1a8000 0x1000 0xa9000 0x1a9000 0x1000 0xaa000 0x1aa000 0x1000 0xab000 0x1ab000 0x1000 0xac000 0x1ac000 0x1000 0xad000 0x1ad000 0x1000 0xae000 0x1ae000 0x1000 0xaf000 0x1af000 0x1000 0xb0000 0x1b0000 0x10000 0xc0000 0x1c0000 0x1000 0xcc000 0x1cc000 0x2000 0xce000 0x1ce000 0x2000 0xd0000 0x1d0000 0x2000 0xd2000 0x1d2000 0x2000 0xd8000 0x1d8000 0x1000 0xd9000 0x1d9000 0x1000 0xa0000 0x1a0000 0x1000 0xa1000 0x1a1000 0x1000 0xa2000 0x1a2000 0x1000 0xa3000 0x1a3000 0x1000 0xa4000 0x1a4000 0x1000 0xa5000 0x1a5000 0x1000>;

				target-module@8c000 {
					#address-cells = <0x01>;
					#size-cells = <0x01>;
					compatible = "ti,sysc";
					ranges = <0x00 0x8c000 0x1000>;
					status = "disabled";
				};

				target-module@8e000 {
					#address-cells = <0x01>;
					#size-cells = <0x01>;
					compatible = "ti,sysc";
					ranges = <0x00 0x8e000 0x1000>;
					status = "disabled";
				};

				target-module@9c000 {
					#address-cells = <0x01>;
					#size-cells = <0x01>;
					clock-names = "fck";
					clocks = <0x38 0x0c 0x00>;
					compatible = "ti,sysc-omap2\0ti,sysc";
					ranges = <0x00 0x9c000 0x1000>;
					reg = <0x9c000 0x08 0x9c010 0x08 0x9c090 0x08>;
					reg-names = "rev\0sysc\0syss";
					ti,sysc-mask = <0x307>;
					ti,sysc-sidle = <0x00 0x01 0x02 0x03>;
					ti,syss-mask = <0x01>;

					i2c@0 {
						#address-cells = <0x01>;
						#size-cells = <0x00>;
						clock-frequency = <0x186a0>;
						compatible = "ti,omap4-i2c";
						interrupts = <0x1e>;
						phandle = <0xbf>;
						pinctrl-0 = <0x41>;
						pinctrl-names = "default";
						reg = <0x00 0x1000>;
						status = "okay";
						symlink = "bone/i2c/2";

						eeprom@54 {
							compatible = "atmel,24c256";
							phandle = <0xc0>;
							reg = <0x54>;

							nvmem-layout {
								#address-cells = <0x01>;
								#size-cells = <0x01>;
								compatible = "fixed-layout";

								cape_data@0 {
									phandle = <0xc1>;
									reg = <0x00 0x100>;
								};
							};
						};

						eeprom@55 {
							compatible = "atmel,24c256";
							phandle = <0xc2>;
							reg = <0x55>;

							nvmem-layout {
								#address-cells = <0x01>;
								#size-cells = <0x01>;
								compatible = "fixed-layout";

								cape_data@0 {
									phandle = <0xc3>;
									reg = <0x00 0x100>;
								};
							};
						};

						eeprom@56 {
							compatible = "atmel,24c256";
							phandle = <0xc4>;
							reg = <0x56>;

							nvmem-layout {
								#address-cells = <0x01>;
								#size-cells = <0x01>;
								compatible = "fixed-layout";

								cape_data@0 {
									phandle = <0xc5>;
									reg = <0x00 0x100>;
								};
							};
						};

						eeprom@57 {
							compatible = "atmel,24c256";
							phandle = <0xc6>;
							reg = <0x57>;

							nvmem-layout {
								#address-cells = <0x01>;
								#size-cells = <0x01>;
								compatible = "fixed-layout";

								cape_data@0 {
									phandle = <0xc7>;
									reg = <0x00 0x100>;
								};
							};
						};
					};
				};

				target-module@a0000 {
					#address-cells = <0x01>;
					#size-cells = <0x01>;
					clock-names = "fck";
					clocks = <0x38 0x18 0x00>;
					compatible = "ti,sysc-omap2\0ti,sysc";
					ranges = <0x00 0xa0000 0x1000>;
					reg = <0xa0000 0x04 0xa0110 0x04 0xa0114 0x04>;
					reg-names = "rev\0sysc\0syss";
					ti,sysc-mask = <0x303>;
					ti,sysc-sidle = <0x00 0x01 0x02>;
					ti,syss-mask = <0x01>;

					spi@0 {
						#address-cells = <0x01>;
						#size-cells = <0x00>;
						compatible = "ti,omap4-mcspi";
						dma-names = "tx0\0rx0\0tx1\0rx1";
						dmas = <0x24 0x2a 0x00 0x24 0x2b 0x00 0x24 0x2c 0x00 0x24 0x2d 0x00>;
						interrupts = <0x7d>;
						phandle = <0xc8>;
						reg = <0x00 0x400>;
						status = "disabled";
						ti,spi-num-cs = <0x02>;
					};
				};

				target-module@a2000 {
					#address-cells = <0x01>;
					#size-cells = <0x01>;
					compatible = "ti,sysc";
					ranges = <0x00 0xa2000 0x1000>;
					status = "disabled";
				};

				target-module@a4000 {
					#address-cells = <0x01>;
					#size-cells = <0x01>;
					compatible = "ti,sysc";
					ranges = <0x00 0xa4000 0x1000>;
					status = "disabled";
				};

				target-module@a6000 {
					#address-cells = <0x01>;
					#size-cells = <0x01>;
					clock-names = "fck";
					clocks = <0x38 0x3c 0x00>;
					compatible = "ti,sysc-omap2\0ti,sysc";
					ranges = <0x00 0xa6000 0x1000>;
					reg = <0xa6050 0x04 0xa6054 0x04 0xa6058 0x04>;
					reg-names = "rev\0sysc\0syss";
					ti,sysc-mask = <0x07>;
					ti,sysc-sidle = <0x00 0x01 0x02 0x03>;

					serial@0 {
						clock-frequency = <0x2dc6c00>;
						compatible = "ti,am3352-uart\0ti,omap3-uart";
						interrupts = <0x2c>;
						phandle = <0xc9>;
						reg = <0x00 0x1000>;
						status = "disabled";
					};
				};

				target-module@a8000 {
					#address-cells = <0x01>;
					#size-cells = <0x01>;
					clock-names = "fck";
					clocks = <0x38 0x40 0x00>;
					compatible = "ti,sysc-omap2\0ti,sysc";
					ranges = <0x00 0xa8000 0x1000>;
					reg = <0xa8050 0x04 0xa8054 0x04 0xa8058 0x04>;
					reg-names = "rev\0sysc\0syss";
					ti,sysc-mask = <0x07>;
					ti,sysc-sidle = <0x00 0x01 0x02 0x03>;

					serial@0 {
						clock-frequency = <0x2dc6c00>;
						compatible = "ti,am3352-uart\0ti,omap3-uart";
						interrupts = <0x2d>;
						phandle = <0xca>;
						pinctrl-0 = <0x42>;
						pinctrl-names = "default";
						reg = <0x00 0x1000>;
						status = "disabled";
						symlink = "bone/uart/4";
					};
				};

				target-module@aa000 {
					#address-cells = <0x01>;
					#size-cells = <0x01>;
					clock-names = "fck";
					clocks = <0x38 0x00 0x00>;
					compatible = "ti,sysc-omap2\0ti,sysc";
					ranges = <0x00 0xaa000 0x1000>;
					reg = <0xaa050 0x04 0xaa054 0x04 0xaa058 0x04>;
					reg-names = "rev\0sysc\0syss";
					ti,sysc-mask = <0x07>;
					ti,sysc-sidle = <0x00 0x01 0x02 0x03>;

					serial@0 {
						clock-frequency = <0x2dc6c00>;
						compatible = "ti,am3352-uart\0ti,omap3-uart";
						interrupts = <0x2e>;
						phandle = <0xcb>;
						reg = <0x00 0x1000>;
						status = "disabled";
					};
				};

				target-module@ac000 {
					#address-cells = <0x01>;
					#size-cells = <0x01>;
					clock-names = "fck\0dbclk";
					clocks = <0x38 0x78 0x00 0x38 0x78 0x12>;
					compatible = "ti,sysc-omap2\0ti,sysc";
					ranges = <0x00 0xac000 0x1000>;
					reg = <0xac000 0x04 0xac010 0x04 0xac114 0x04>;
					reg-names = "rev\0sysc\0syss";
					ti,sysc-mask = <0x07>;
					ti,sysc-sidle = <0x00 0x01 0x02 0x03>;
					ti,syss-mask = <0x01>;

					gpio@0 {
						#gpio-cells = <0x02>;
						#interrupt-cells = <0x02>;
						compatible = "ti,omap4-gpio";
						gpio-controller;
						gpio-line-names = "P9_15B\0P8_18\0P8_7\0P8_8\0P8_10\0P8_9\0P8_45 [hdmi]\0P8_46 [hdmi]\0P8_43 [hdmi]\0P8_44 [hdmi]\0P8_41 [hdmi]\0P8_42 [hdmi]\0P8_39 [hdmi]\0P8_40 [hdmi]\0P8_37 [hdmi]\0P8_38 [hdmi]\0P8_36 [hdmi]\0P8_34 [hdmi]\0[rmii1_rxd3]\0[rmii1_rxd2]\0[rmii1_rxd1]\0[rmii1_rxd0]\0P8_27 [hdmi]\0P8_29 [hdmi]\0P8_28 [hdmi]\0P8_30 [hdmi]\0[mmc0_dat3]\0[mmc0_dat2]\0[mmc0_dat1]\0[mmc0_dat0]\0[mmc0_clk]\0[mmc0_cmd]";
						gpio-ranges = <0x23 0x00 0x22 0x12 0x23 0x12 0x4d 0x04 0x23 0x16 0x38 0x0a>;
						interrupt-controller;
						interrupts = <0x20>;
						phandle = <0xcc>;
						reg = <0x00 0x1000>;
					};
				};

				target-module@ae000 {
					#address-cells = <0x01>;
					#size-cells = <0x01>;
					clock-names = "fck\0dbclk";
					clocks = <0x38 0x7c 0x00 0x38 0x7c 0x12>;
					compatible = "ti,sysc-omap2\0ti,sysc";
					phandle = <0xcd>;
					ranges = <0x00 0xae000 0x1000>;
					reg = <0xae000 0x04 0xae010 0x04 0xae114 0x04>;
					reg-names = "rev\0sysc\0syss";
					ti,sysc-mask = <0x07>;
					ti,sysc-sidle = <0x00 0x01 0x02 0x03>;
					ti,syss-mask = <0x01>;

					gpio@0 {
						#gpio-cells = <0x02>;
						#interrupt-cells = <0x02>;
						compatible = "ti,omap4-gpio";
						gpio-controller;
						gpio-line-names = "[mii col]\0[mii crs]\0[mii rx err]\0[mii tx en]\0[mii rx dv]\0[i2c0 sda]\0[i2c0 scl]\0[jtag emu0]\0[jtag emu1]\0[mii tx clk]\0[mii rx clk]\0NC\0NC\0[usb vbus en]\0P9_31 [spi1_sclk]\0P9_29 [spi1_d0]\0P9_30 [spi1_d1]\0P9_28 [spi1_cs0]\0P9_42B [ecappwm0]\0P9_27\0P9_41A\0P9_25\0NC\0NC\0NC\0NC\0NC\0NC\0NC\0NC\0NC\0NC";
						gpio-ranges = <0x23 0x00 0x42 0x05 0x23 0x05 0x62 0x02 0x23 0x07 0x4b 0x02 0x23 0x0d 0x8d 0x01 0x23 0x0e 0x64 0x08>;
						interrupt-controller;
						interrupts = <0x3e>;
						phandle = <0xce>;
						reg = <0x00 0x1000>;
					};
				};

				target-module@b0000 {
					#address-cells = <0x01>;
					#size-cells = <0x01>;
					compatible = "ti,sysc";
					ranges = <0x00 0xb0000 0x10000>;
					status = "disabled";
				};

				target-module@cc000 {
					#address-cells = <0x01>;
					#size-cells = <0x01>;
					clock-names = "fck\0osc";
					clocks = <0x38 0x88 0x00 0x43>;
					compatible = "ti,sysc-omap4\0ti,sysc";
					ranges = <0x00 0xcc000 0x2000>;
					reg = <0xcc020 0x04>;
					reg-names = "rev";

					can@0 {
						clock-names = "fck";
						clocks = <0x43>;
						compatible = "ti,am3352-d_can";
						interrupts = <0x34>;
						phandle = <0xcf>;
						reg = <0x00 0x2000>;
						status = "disabled";
						syscon-raminit = <0x06 0x644 0x00>;
					};
				};

				target-module@d0000 {
					#address-cells = <0x01>;
					#size-cells = <0x01>;
					clock-names = "fck\0osc";
					clocks = <0x38 0x8c 0x00 0x44>;
					compatible = "ti,sysc-omap4\0ti,sysc";
					ranges = <0x00 0xd0000 0x2000>;
					reg = <0xd0020 0x04>;
					reg-names = "rev";

					can@0 {
						clock-names = "fck";
						clocks = <0x44>;
						compatible = "ti,am3352-d_can";
						interrupts = <0x37>;
						phandle = <0xd0>;
						pinctrl-0 = <0x45>;
						pinctrl-names = "default";
						reg = <0x00 0x2000>;
						status = "disabled";
						symlink = "bone/can/1";
						syscon-raminit = <0x06 0x644 0x01>;
					};
				};

				target-module@d8000 {
					#address-cells = <0x01>;
					#size-cells = <0x01>;
					clock-names = "fck";
					clocks = <0x38 0xbc 0x00>;
					compatible = "ti,sysc-omap2\0ti,sysc";
					ranges = <0x00 0xd8000 0x1000>;
					reg = <0xd82fc 0x04 0xd8110 0x04 0xd8114 0x04>;
					reg-names = "rev\0sysc\0syss";
					ti,sysc-mask = <0x307>;
					ti,sysc-sidle = <0x00 0x01 0x02>;
					ti,syss-mask = <0x01>;

					mmc@0 {
						bus-width = <0x08>;
						compatible = "ti,am335-sdhci";
						dma-names = "tx\0rx";
						dmas = <0x24 0x02 0x00 0x24 0x03 0x00>;
						interrupts = <0x1c>;
						non-removable;
						phandle = <0xd1>;
						pinctrl-0 = <0x46>;
						pinctrl-names = "default";
						reg = <0x00 0x1000>;
						status = "okay";
						ti,needs-special-reset;
						vmmc-supply = <0x40>;
					};
				};
			};

			segment@200000 {
				#address-cells = <0x01>;
				#size-cells = <0x01>;
				compatible = "simple-pm-bus";
				ranges = <0x00 0x200000 0x10000>;

				target-module@0 {
					#address-cells = <0x01>;
					#size-cells = <0x01>;
					clock-names = "fck";
					clocks = <0x48 0x04 0x00>;
					compatible = "ti,sysc-omap4-simple\0ti,sysc";
					power-domains = <0x47>;
					ranges = <0x00 0x00 0x10000>;
					ti,no-idle;

					mpu@0 {
						compatible = "ti,omap3-mpu";
						pm-sram = <0x49 0x4a>;
					};
				};
			};

			segment@300000 {
				#address-cells = <0x01>;
				#size-cells = <0x01>;
				compatible = "simple-pm-bus";
				ranges = <0x00 0x300000 0x1000 0x1000 0x301000 0x1000 0x2000 0x302000 0x1000 0x3000 0x303000 0x1000 0x4000 0x304000 0x1000 0x5000 0x305000 0x1000 0xe000 0x30e000 0x1000 0xf000 0x30f000 0x1000 0x18000 0x318000 0x4000 0x1c000 0x31c000 0x1000 0x10000 0x310000 0x2000 0x12000 0x312000 0x1000 0x15000 0x315000 0x1000 0x16000 0x316000 0x1000 0x17000 0x317000 0x1000 0x13000 0x313000 0x1000 0x14000 0x314000 0x1000 0x20000 0x320000 0x1000 0x21000 0x321000 0x1000 0x22000 0x322000 0x1000 0x23000 0x323000 0x1000 0x24000 0x324000 0x1000 0x25000 0x325000 0x1000>;

				target-module@0 {
					#address-cells = <0x01>;
					#size-cells = <0x01>;
					clock-names = "fck";
					clocks = <0x38 0x9c 0x00>;
					compatible = "ti,sysc-omap4\0ti,sysc";
					ranges = <0x00 0x00 0x1000>;
					reg = <0x00 0x04 0x04 0x04>;
					reg-names = "rev\0sysc";
					ti,sysc-midle = <0x00 0x01 0x02 0x03>;
					ti,sysc-sidle = <0x00 0x01 0x02 0x03>;

					epwmss@0 {
						#address-cells = <0x01>;
						#size-cells = <0x01>;
						compatible = "ti,am33xx-pwmss";
						phandle = <0xd2>;
						ranges = <0x00 0x00 0x1000>;
						reg = <0x00 0x10>;
						status = "disabled";

						counter@180 {
							clock-names = "sysclkout";
							clocks = <0x31>;
							compatible = "ti,am3352-eqep";
							interrupts = <0x4f>;
							phandle = <0xd4>;
							reg = <0x180 0x80>;
							status = "disabled";
						};

						pwm@100 {
							#pwm-cells = <0x03>;
							clock-names = "fck";
							clocks = <0x31>;
							compatible = "ti,am3352-ecap";
							phandle = <0xd3>;
							reg = <0x100 0x80>;
							status = "disabled";
						};

						pwm@200 {
							#pwm-cells = <0x03>;
							clock-names = "tbclk\0fck";
							clocks = <0x4b 0x31>;
							compatible = "ti,am3352-ehrpwm";
							phandle = <0xd5>;
							reg = <0x200 0x80>;
							status = "disabled";
						};
					};
				};

				target-module@10000 {
					#address-cells = <0x01>;
					#size-cells = <0x01>;
					clock-names = "fck";
					clocks = <0x38 0x58 0x00>;
					compatible = "ti,sysc-omap2\0ti,sysc";
					ranges = <0x00 0x10000 0x2000>;
					reg = <0x11fe0 0x04 0x11fe4 0x04>;
					reg-names = "rev\0sysc";
					ti,sysc-mask = <0x01>;
					ti,sysc-sidle = <0x00 0x01>;

					rng@0 {
						compatible = "ti,omap4-rng";
						interrupts = <0x6f>;
						phandle = <0xdf>;
						reg = <0x00 0x2000>;
					};
				};

				target-module@13000 {
					#address-cells = <0x01>;
					#size-cells = <0x01>;
					compatible = "ti,sysc";
					ranges = <0x00 0x13000 0x1000>;
					status = "disabled";
				};

				target-module@15000 {
					#address-cells = <0x01>;
					#size-cells = <0x01>;
					compatible = "ti,sysc";
					ranges = <0x00 0x15000 0x1000 0x1000 0x16000 0x1000>;
					status = "disabled";
				};

				target-module@18000 {
					#address-cells = <0x01>;
					#size-cells = <0x01>;
					compatible = "ti,sysc";
					ranges = <0x00 0x18000 0x4000>;
					status = "disabled";
				};

				target-module@2000 {
					#address-cells = <0x01>;
					#size-cells = <0x01>;
					clock-names = "fck";
					clocks = <0x38 0x94 0x00>;
					compatible = "ti,sysc-omap4\0ti,sysc";
					ranges = <0x00 0x2000 0x1000>;
					reg = <0x2000 0x04 0x2004 0x04>;
					reg-names = "rev\0sysc";
					ti,sysc-midle = <0x00 0x01 0x02 0x03>;
					ti,sysc-sidle = <0x00 0x01 0x02 0x03>;

					epwmss@0 {
						#address-cells = <0x01>;
						#size-cells = <0x01>;
						compatible = "ti,am33xx-pwmss";
						phandle = <0xd6>;
						ranges = <0x00 0x00 0x1000>;
						reg = <0x00 0x10>;
						status = "disabled";

						counter@180 {
							clock-names = "sysclkout";
							clocks = <0x31>;
							compatible = "ti,am3352-eqep";
							interrupts = <0x58>;
							phandle = <0xd8>;
							reg = <0x180 0x80>;
							status = "disabled";
						};

						pwm@100 {
							#pwm-cells = <0x03>;
							clock-names = "fck";
							clocks = <0x31>;
							compatible = "ti,am3352-ecap";
							phandle = <0xd7>;
							reg = <0x100 0x80>;
							status = "disabled";
						};

						pwm@200 {
							#pwm-cells = <0x03>;
							clock-names = "tbclk\0fck";
							clocks = <0x4c 0x31>;
							compatible = "ti,am3352-ehrpwm";
							phandle = <0xd9>;
							reg = <0x200 0x80>;
							status = "disabled";
						};
					};
				};

				target-module@20000 {
					#address-cells = <0x01>;
					#size-cells = <0x01>;
					compatible = "ti,sysc";
					ranges = <0x00 0x20000 0x1000>;
					status = "disabled";
				};

				target-module@22000 {
					#address-cells = <0x01>;
					#size-cells = <0x01>;
					compatible = "ti,sysc";
					ranges = <0x00 0x22000 0x1000>;
					status = "disabled";
				};

				target-module@24000 {
					#address-cells = <0x01>;
					#size-cells = <0x01>;
					compatible = "ti,sysc";
					ranges = <0x00 0x24000 0x1000>;
					status = "disabled";
				};

				target-module@4000 {
					#address-cells = <0x01>;
					#size-cells = <0x01>;
					clock-names = "fck";
					clocks = <0x38 0xa0 0x00>;
					compatible = "ti,sysc-omap4\0ti,sysc";
					ranges = <0x00 0x4000 0x1000>;
					reg = <0x4000 0x04 0x4004 0x04>;
					reg-names = "rev\0sysc";
					ti,sysc-midle = <0x00 0x01 0x02 0x03>;
					ti,sysc-sidle = <0x00 0x01 0x02 0x03>;

					epwmss@0 {
						#address-cells = <0x01>;
						#size-cells = <0x01>;
						compatible = "ti,am33xx-pwmss";
						phandle = <0xda>;
						ranges = <0x00 0x00 0x1000>;
						reg = <0x00 0x10>;
						status = "disabled";

						counter@180 {
							clock-names = "sysclkout";
							clocks = <0x31>;
							compatible = "ti,am3352-eqep";
							interrupts = <0x59>;
							phandle = <0xdc>;
							reg = <0x180 0x80>;
							status = "disabled";
						};

						pwm@100 {
							#pwm-cells = <0x03>;
							clock-names = "fck";
							clocks = <0x31>;
							compatible = "ti,am3352-ecap";
							phandle = <0xdb>;
							reg = <0x100 0x80>;
							status = "disabled";
						};

						pwm@200 {
							#pwm-cells = <0x03>;
							clock-names = "tbclk\0fck";
							clocks = <0x4d 0x31>;
							compatible = "ti,am3352-ehrpwm";
							phandle = <0xdd>;
							reg = <0x200 0x80>;
							status = "disabled";
						};
					};
				};

				target-module@e000 {
					#address-cells = <0x01>;
					#size-cells = <0x01>;
					clock-names = "fck";
					clocks = <0x4e 0x00 0x00>;
					compatible = "ti,sysc-omap4\0ti,sysc";
					ranges = <0x00 0xe000 0x1000>;
					reg = <0xe000 0x04 0xe054 0x04>;
					reg-names = "rev\0sysc";
					ti,sysc-midle = <0x00 0x01 0x02>;
					ti,sysc-sidle = <0x00 0x01 0x02>;

					lcdc@0 {
						blue-and-red-wiring = "straight";
						compatible = "ti,am33xx-tilcdc";
						interrupts = <0x24>;
						phandle = <0xde>;
						reg = <0x00 0x1000>;
						status = "okay";

						port {

							endpoint@0 {
								phandle = <0x2b>;
								remote-endpoint = <0x4f>;
							};
						};
					};
				};
			};
		};

		interconnect@4a000000 {
			#address-cells = <0x01>;
			#size-cells = <0x01>;
			clock-names = "fck";
			clocks = <0x50 0x00 0x00>;
			compatible = "ti,am33xx-l4-fast\0simple-pm-bus";
			phandle = <0xe1>;
			power-domains = <0x09>;
			ranges = <0x00 0x4a000000 0x1000000>;
			reg = <0x4a000000 0x800 0x4a000800 0x800 0x4a001000 0x400>;
			reg-names = "ap\0la\0ia0";

			segment@0 {
				#address-cells = <0x01>;
				#size-cells = <0x01>;
				compatible = "simple-pm-bus";
				ranges = <0x00 0x00 0x800 0x800 0x800 0x800 0x1000 0x1000 0x400 0x100000 0x100000 0x8000 0x108000 0x108000 0x1000 0x180000 0x180000 0x20000 0x1a0000 0x1a0000 0x1000 0x200000 0x200000 0x80000 0x280000 0x280000 0x1000 0x300000 0x300000 0x80000 0x380000 0x380000 0x1000>;

				target-module@100000 {
					#address-cells = <0x01>;
					#size-cells = <0x01>;
					clock-names = "fck";
					clocks = <0x51 0x14 0x00>;
					compatible = "ti,sysc-omap4-simple\0ti,sysc";
					ranges = <0x00 0x100000 0x8000>;
					reg = <0x101200 0x04 0x101208 0x04 0x101204 0x04>;
					reg-names = "rev\0sysc\0syss";
					ti,sysc-mask = <0x00>;
					ti,sysc-midle = <0x00 0x01>;
					ti,sysc-sidle = <0x00 0x01>;
					ti,syss-mask = <0x01>;

					ethernet@0 {
						#address-cells = <0x01>;
						#size-cells = <0x01>;
						active_slave = <0x00>;
						ale_entries = <0x400>;
						bd_ram_size = <0x2000>;
						clock-names = "fck\0cpts";
						clocks = <0x52 0x53>;
						compatible = "ti,am335x-cpsw\0ti,cpsw";
						cpdma_channels = <0x08>;
						cpts_clock_mult = <0x80000000>;
						cpts_clock_shift = <0x1d>;
						interrupts = <0x28 0x29 0x2a 0x2b>;
						mac_control = <0x20>;
						phandle = <0xe2>;
						ranges = <0x00 0x00 0x8000>;
						reg = <0x00 0x800 0x1200 0x100>;
						slaves = <0x02>;
						status = "disabled";
						syscon = <0x06>;

						mdio@1000 {
							#address-cells = <0x01>;
							#size-cells = <0x00>;
							bus_freq = <0xf4240>;
							clock-names = "fck";
							clocks = <0x51 0x14 0x00>;
							compatible = "ti,cpsw-mdio\0ti,davinci_mdio";
							phandle = <0xe3>;
							reg = <0x1000 0x100>;
							status = "disabled";
						};

						slave@200 {
							mac-address = [00 00 00 00 00 00];
							phandle = <0xe4>;
							phys = <0x54 0x01 0x01>;
						};

						slave@300 {
							mac-address = [00 00 00 00 00 00];
							phandle = <0xe5>;
							phys = <0x54 0x02 0x01>;
						};
					};

					switch@0 {
						#address-cells = <0x01>;
						#size-cells = <0x01>;
						clock-names = "fck";
						clocks = <0x52>;
						compatible = "ti,am335x-cpsw-switch\0ti,cpsw-switch";
						interrupt-names = "rx_thresh\0rx\0tx\0misc";
						interrupts = <0x28 0x29 0x2a 0x2b>;
						phandle = <0xe6>;
						pinctrl-0 = <0x55>;
						pinctrl-1 = <0x56>;
						pinctrl-names = "default\0sleep";
						ranges = <0x00 0x00 0x4000>;
						reg = <0x00 0x4000>;
						status = "okay";
						syscon = <0x06>;

						cpts {
							clock-names = "cpts";
							clocks = <0x53>;
						};

						ethernet-ports {
							#address-cells = <0x01>;
							#size-cells = <0x00>;

							port@1 {
								label = "port1";
								mac-address = [00 00 00 00 00 00];
								phandle = <0xe7>;
								phy-handle = <0x57>;
								phy-mode = "mii";
								phys = <0x54 0x01 0x01>;
								reg = <0x01>;
								ti,dual-emac-pvid = <0x01>;
							};

							port@2 {
								label = "port2";
								mac-address = [00 00 00 00 00 00];
								phandle = <0xe8>;
								phys = <0x54 0x02 0x01>;
								reg = <0x02>;
								status = "disabled";
							};
						};

						mdio@1000 {
							#address-cells = <0x01>;
							#size-cells = <0x00>;
							bus_freq = <0xf4240>;
							clock-names = "fck";
							clocks = <0x52>;
							compatible = "ti,cpsw-mdio\0ti,davinci_mdio";
							phandle = <0xe9>;
							pinctrl-0 = <0x58>;
							pinctrl-1 = <0x59>;
							pinctrl-names = "default\0sleep";
							reg = <0x1000 0x100>;

							ethernet-phy@0 {
								phandle = <0x57>;
								reg = <0x00>;
								reset-assert-us = <0x12c>;
								reset-deassert-us = <0xc350>;
								reset-gpios = <0x28 0x08 0x01>;
								smsc,disable-energy-detect;
							};
						};
					};
				};

				target-module@180000 {
					#address-cells = <0x01>;
					#size-cells = <0x01>;
					compatible = "ti,sysc";
					ranges = <0x00 0x180000 0x20000>;
					status = "disabled";
				};

				target-module@200000 {
					#address-cells = <0x01>;
					#size-cells = <0x01>;
					compatible = "ti,sysc";
					ranges = <0x00 0x200000 0x80000>;
					status = "disabled";
				};

				target-module@300000 {
					#address-cells = <0x01>;
					#size-cells = <0x01>;
					clock-names = "fck";
					clocks = <0x5a 0x00 0x00>;
					compatible = "ti,sysc-pruss\0ti,sysc";
					phandle = <0xea>;
					ranges = <0x00 0x300000 0x80000>;
					reg = <0x326000 0x04 0x326004 0x04>;
					reg-names = "rev\0sysc";
					reset-names = "rstctrl";
					resets = <0x09 0x01>;
					status = "okay";
					ti,sysc-mask = <0x30>;
					ti,sysc-midle = <0x00 0x01 0x02>;
					ti,sysc-sidle = <0x00 0x01 0x02>;

					pruss@0 {
						#address-cells = <0x01>;
						#size-cells = <0x01>;
						compatible = "ti,am3356-pruss";
						phandle = <0xeb>;
						ranges;
						reg = <0x00 0x80000>;

						cfg@26000 {
							#address-cells = <0x01>;
							#size-cells = <0x01>;
							compatible = "ti,pruss-cfg\0syscon";
							phandle = <0xed>;
							ranges = <0x00 0x26000 0x2000>;
							reg = <0x26000 0x2000>;

							clocks {
								#address-cells = <0x01>;
								#size-cells = <0x00>;

								iepclk-mux@30 {
									#clock-cells = <0x00>;
									clocks = <0x17 0x5b>;
									phandle = <0xee>;
									reg = <0x30>;
								};
							};
						};

						interrupt-controller@20000 {
							#interrupt-cells = <0x03>;
							compatible = "ti,pruss-intc";
							interrupt-controller;
							interrupt-names = "host_intr0\0host_intr1\0host_intr2\0host_intr3\0host_intr4\0host_intr5\0host_intr6\0host_intr7";
							interrupts = <0x14 0x15 0x16 0x17 0x18 0x19 0x1a 0x1b>;
							phandle = <0xf0>;
							reg = <0x20000 0x2000>;
						};

						mdio@32400 {
							#address-cells = <0x01>;
							#size-cells = <0x00>;
							bus_freq = <0xf4240>;
							clock-names = "fck";
							clocks = <0x16>;
							compatible = "ti,davinci_mdio";
							phandle = <0xf3>;
							reg = <0x32400 0x90>;
							status = "disabled";
						};

						memories@0 {
							phandle = <0xec>;
							reg = <0x00 0x2000 0x2000 0x2000 0x10000 0x3000>;
							reg-names = "dram0\0dram1\0shrdram2";
						};

						mii-rt@32000 {
							compatible = "ti,pruss-mii\0syscon";
							phandle = <0xef>;
							reg = <0x32000 0x58>;
						};

						pru@34000 {
							compatible = "ti,am3356-pru";
							firmware-name = "am335x-pru0-fw";
							phandle = <0xf1>;
							reg = <0x34000 0x2000 0x22000 0x400 0x22400 0x100>;
							reg-names = "iram\0control\0debug";
						};

						pru@38000 {
							compatible = "ti,am3356-pru";
							firmware-name = "am335x-pru1-fw";
							phandle = <0xf2>;
							reg = <0x38000 0x2000 0x24000 0x400 0x24400 0x100>;
							reg-names = "iram\0control\0debug";
						};
					};
				};
			};
		};

		interconnect@4b140000 {
			#address-cells = <0x01>;
			#size-cells = <0x01>;
			compatible = "ti,am33xx-l4-mpuss\0simple-bus";
			phandle = <0xf4>;
			ranges = <0x00 0x4b140000 0x8000>;
			reg = <0x4b144400 0x100 0x4b144800 0x400>;
			reg-names = "la\0ap";

			segment@0 {
				#address-cells = <0x01>;
				#size-cells = <0x01>;
				compatible = "simple-bus";
				ranges = <0x4800 0x4800 0x400 0x1000 0x1000 0x1000 0x2000 0x2000 0x1000 0x4000 0x4000 0x400 0x5000 0x5000 0x400 0x00 0x00 0x1000 0x3000 0x3000 0x1000 0x800 0x800 0x800>;

				target-module@0 {
					#address-cells = <0x01>;
					#size-cells = <0x01>;
					compatible = "ti,sysc";
					ranges = <0x00 0x00 0x1000 0x1000 0x1000 0x1000 0x2000 0x2000 0x1000>;
					status = "disabled";
				};

				target-module@3000 {
					#address-cells = <0x01>;
					#size-cells = <0x01>;
					compatible = "ti,sysc";
					ranges = <0x00 0x3000 0x1000>;
					status = "disabled";
				};
			};
		};

		interrupt-controller@48200000 {
			#interrupt-cells = <0x01>;
			compatible = "ti,am33xx-intc";
			interrupt-controller;
			phandle = <0x01>;
			reg = <0x48200000 0x1000>;
		};

		target-module@40300000 {
			#address-cells = <0x01>;
			#size-cells = <0x01>;
			clock-names = "fck";
			clocks = <0x07 0x08 0x00>;
			compatible = "ti,sysc-omap4-simple\0ti,sysc";
			ranges = <0x00 0x40300000 0x10000>;
			ti,no-idle;

			sram@0 {
				#address-cells = <0x01>;
				#size-cells = <0x01>;
				compatible = "mmio-sram";
				phandle = <0xf9>;
				ranges = <0x00 0x00 0x10000>;
				reg = <0x00 0x10000>;

				pm-code-sram@0 {
					compatible = "ti,sram";
					phandle = <0x49>;
					protect-exec;
					reg = <0x00 0x1000>;
				};

				pm-data-sram@1000 {
					compatible = "ti,sram";
					phandle = <0x4a>;
					pool;
					reg = <0x1000 0x1000>;
				};
			};
		};

		target-module@47400000 {
			#address-cells = <0x01>;
			#size-cells = <0x01>;
			clock-names = "fck";
			clocks = <0x3b 0x00 0x00>;
			compatible = "ti,sysc-omap4\0ti,sysc";
			phandle = <0xf6>;
			ranges = <0x00 0x47400000 0x8000>;
			reg = <0x47400000 0x04 0x47400010 0x04>;
			reg-names = "rev\0sysc";
			ti,sysc-delay-us = <0x02>;
			ti,sysc-mask = <0x03>;
			ti,sysc-midle = <0x00 0x01 0x02>;
			ti,sysc-sidle = <0x00 0x01 0x02 0x03>;

			dma-controller@2000 {
				#dma-cells = <0x02>;
				#dma-channels = <0x1e>;
				#dma-requests = <0x100>;
				compatible = "ti,am3359-cppi41";
				dma-channels = <0x1e>;
				dma-requests = <0x100>;
				interrupt-names = "glue";
				interrupts = <0x11>;
				phandle = <0x61>;
				reg = <0x00 0x1000 0x2000 0x1000 0x3000 0x1000 0x4000 0x4000>;
				reg-names = "glue\0controller\0scheduler\0queuemgr";
			};

			usb-phy@1300 {
				#phy-cells = <0x00>;
				compatible = "ti,am335x-usb-phy";
				phandle = <0x60>;
				reg = <0x1300 0x100>;
				reg-names = "phy";
				ti,ctrl_mod = <0x5f>;
			};

			usb-phy@1b00 {
				#phy-cells = <0x00>;
				compatible = "ti,am335x-usb-phy";
				phandle = <0x63>;
				reg = <0x1b00 0x100>;
				reg-names = "phy";
				ti,ctrl_mod = <0x5f>;
			};

			usb@1400 {
				compatible = "ti,musb-am33xx";
				dma-names = "rx1\0rx2\0rx3\0rx4\0rx5\0rx6\0rx7\0rx8\0rx9\0rx10\0rx11\0rx12\0rx13\0rx14\0rx15\0tx1\0tx2\0tx3\0tx4\0tx5\0tx6\0tx7\0tx8\0tx9\0tx10\0tx11\0tx12\0tx13\0tx14\0tx15";
				dmas = <0x61 0x00 0x00 0x61 0x01 0x00 0x61 0x02 0x00 0x61 0x03 0x00 0x61 0x04 0x00 0x61 0x05 0x00 0x61 0x06 0x00 0x61 0x07 0x00 0x61 0x08 0x00 0x61 0x09 0x00 0x61 0x0a 0x00 0x61 0x0b 0x00 0x61 0x0c 0x00 0x61 0x0d 0x00 0x61 0x0e 0x00 0x61 0x00 0x01 0x61 0x01 0x01 0x61 0x02 0x01 0x61 0x03 0x01 0x61 0x04 0x01 0x61 0x05 0x01 0x61 0x06 0x01 0x61 0x07 0x01 0x61 0x08 0x01 0x61 0x09 0x01 0x61 0x0a 0x01 0x61 0x0b 0x01 0x61 0x0c 0x01 0x61 0x0d 0x01 0x61 0x0e 0x01>;
				dr_mode = "peripheral";
				interrupt-names = "mc\0vbus";
				interrupts = <0x12>;
				interrupts-extended = <0x01 0x12 0x62 0x00>;
				mentor,multipoint = <0x01>;
				mentor,num-eps = <0x10>;
				mentor,power = <0x1f4>;
				mentor,ram-bits = <0x0c>;
				phandle = <0xf7>;
				phys = <0x60>;
				reg = <0x1400 0x400 0x1000 0x200>;
				reg-names = "mc\0control";
			};

			usb@1800 {
				compatible = "ti,musb-am33xx";
				dma-names = "rx1\0rx2\0rx3\0rx4\0rx5\0rx6\0rx7\0rx8\0rx9\0rx10\0rx11\0rx12\0rx13\0rx14\0rx15\0tx1\0tx2\0tx3\0tx4\0tx5\0tx6\0tx7\0tx8\0tx9\0tx10\0tx11\0tx12\0tx13\0tx14\0tx15";
				dmas = <0x61 0x0f 0x00 0x61 0x10 0x00 0x61 0x11 0x00 0x61 0x12 0x00 0x61 0x13 0x00 0x61 0x14 0x00 0x61 0x15 0x00 0x61 0x16 0x00 0x61 0x17 0x00 0x61 0x18 0x00 0x61 0x19 0x00 0x61 0x1a 0x00 0x61 0x1b 0x00 0x61 0x1c 0x00 0x61 0x1d 0x00 0x61 0x0f 0x01 0x61 0x10 0x01 0x61 0x11 0x01 0x61 0x12 0x01 0x61 0x13 0x01 0x61 0x14 0x01 0x61 0x15 0x01 0x61 0x16 0x01 0x61 0x17 0x01 0x61 0x18 0x01 0x61 0x19 0x01 0x61 0x1a 0x01 0x61 0x1b 0x01 0x61 0x1c 0x01 0x61 0x1d 0x01>;
				dr_mode = "host";
				interrupt-names = "mc";
				interrupts = <0x13>;
				mentor,multipoint = <0x01>;
				mentor,num-eps = <0x10>;
				mentor,power = <0x1f4>;
				mentor,ram-bits = <0x0c>;
				phandle = <0xf8>;
				phys = <0x63>;
				reg = <0x1c00 0x400 0x1800 0x200>;
				reg-names = "mc\0control";
			};
		};

		target-module@47810000 {
			#address-cells = <0x01>;
			#size-cells = <0x01>;
			clock-names = "fck";
			clocks = <0x3b 0xdc 0x00>;
			compatible = "ti,sysc-omap2\0ti,sysc";
			ranges = <0x00 0x47810000 0x1000>;
			reg = <0x478102fc 0x04 0x47810110 0x04 0x47810114 0x04>;
			reg-names = "rev\0sysc\0syss";
			ti,sysc-mask = <0x307>;
			ti,sysc-sidle = <0x00 0x01 0x02>;
			ti,syss-mask = <0x01>;

			mmc@0 {
				compatible = "ti,am335-sdhci";
				interrupts = <0x1d>;
				phandle = <0xf5>;
				reg = <0x00 0x1000>;
				status = "disabled";
				ti,needs-special-reset;
			};
		};

		target-module@49000000 {
			#address-cells = <0x01>;
			#size-cells = <0x01>;
			clock-names = "fck";
			clocks = <0x07 0x98 0x00>;
			compatible = "ti,sysc-omap4\0ti,sysc";
			ranges = <0x00 0x49000000 0x10000>;
			reg = <0x49000000 0x04>;
			reg-names = "rev";

			dma@0 {
				#dma-cells = <0x02>;
				compatible = "ti,edma3-tpcc";
				dma-requests = <0x40>;
				interrupt-names = "edma3_ccint\0edma3_mperr\0edma3_ccerrint";
				interrupts = <0x0c 0x0d 0x0e>;
				phandle = <0x24>;
				reg = <0x00 0x10000>;
				reg-names = "edma3_cc";
				ti,edma-memcpy-channels = <0x14 0x15>;
				ti,tptcs = <0x5c 0x07 0x5d 0x05 0x5e 0x00>;
			};
		};

		target-module@49800000 {
			#address-cells = <0x01>;
			#size-cells = <0x01>;
			clock-names = "fck";
			clocks = <0x07 0x00 0x00>;
			compatible = "ti,sysc-omap4\0ti,sysc";
			ranges = <0x00 0x49800000 0x100000>;
			reg = <0x49800000 0x04 0x49800010 0x04>;
			reg-names = "rev\0sysc";
			ti,sysc-mask = <0x01>;
			ti,sysc-midle = <0x00>;
			ti,sysc-sidle = <0x00 0x02>;

			dma@0 {
				compatible = "ti,edma3-tptc";
				interrupt-names = "edma3_tcerrint";
				interrupts = <0x70>;
				phandle = <0x5c>;
				reg = <0x00 0x100000>;
			};
		};

		target-module@49900000 {
			#address-cells = <0x01>;
			#size-cells = <0x01>;
			clock-names = "fck";
			clocks = <0x07 0xd8 0x00>;
			compatible = "ti,sysc-omap4\0ti,sysc";
			ranges = <0x00 0x49900000 0x100000>;
			reg = <0x49900000 0x04 0x49900010 0x04>;
			reg-names = "rev\0sysc";
			ti,sysc-mask = <0x01>;
			ti,sysc-midle = <0x00>;
			ti,sysc-sidle = <0x00 0x02>;

			dma@0 {
				compatible = "ti,edma3-tptc";
				interrupt-names = "edma3_tcerrint";
				interrupts = <0x71>;
				phandle = <0x5d>;
				reg = <0x00 0x100000>;
			};
		};

		target-module@49a00000 {
			#address-cells = <0x01>;
			#size-cells = <0x01>;
			clock-names = "fck";
			clocks = <0x07 0xdc 0x00>;
			compatible = "ti,sysc-omap4\0ti,sysc";
			ranges = <0x00 0x49a00000 0x100000>;
			reg = <0x49a00000 0x04 0x49a00010 0x04>;
			reg-names = "rev\0sysc";
			ti,sysc-mask = <0x01>;
			ti,sysc-midle = <0x00>;
			ti,sysc-sidle = <0x00 0x02>;

			dma@0 {
				compatible = "ti,edma3-tptc";
				interrupt-names = "edma3_tcerrint";
				interrupts = <0x72>;
				phandle = <0x5e>;
				reg = <0x00 0x100000>;
			};
		};

		target-module@4c000000 {
			#address-cells = <0x01>;
			#size-cells = <0x01>;
			clock-names = "fck";
			clocks = <0x07 0x04 0x00>;
			compatible = "ti,sysc-omap4-simple\0ti,sysc";
			ranges = <0x00 0x4c000000 0x1000000>;
			reg = <0x4c000000 0x04>;
			reg-names = "rev";
			ti,no-idle;

			emif@0 {
				compatible = "ti,emif-am3352";
				interrupts = <0x65>;
				phandle = <0xfa>;
				reg = <0x00 0x1000000>;
				sram = <0x49 0x4a>;
			};
		};

		target-module@50000000 {
			#address-cells = <0x01>;
			#size-cells = <0x01>;
			clock-names = "fck";
			clocks = <0x3b 0x14 0x00>;
			compatible = "ti,sysc-omap2\0ti,sysc";
			ranges = <0x50000000 0x50000000 0x1000 0x00 0x00 0x40000000>;
			reg = <0x50000000 0x04 0x50000010 0x04 0x50000014 0x04>;
			reg-names = "rev\0sysc\0syss";
			ti,sysc-sidle = <0x00 0x01 0x02>;
			ti,syss-mask = <0x01>;

			gpmc@50000000 {
				#address-cells = <0x02>;
				#gpio-cells = <0x02>;
				#interrupt-cells = <0x02>;
				#size-cells = <0x01>;
				compatible = "ti,am3352-gpmc";
				dma-names = "rxtx";
				dmas = <0x24 0x34 0x00>;
				gpio-controller;
				gpmc,num-cs = <0x07>;
				gpmc,num-waitpins = <0x02>;
				interrupt-controller;
				interrupts = <0x64>;
				phandle = <0xfb>;
				reg = <0x50000000 0x2000>;
				status = "disabled";
			};
		};

		target-module@53100000 {
			#address-cells = <0x01>;
			#size-cells = <0x01>;
			clock-names = "fck";
			clocks = <0x07 0x7c 0x00>;
			compatible = "ti,sysc-omap3-sham\0ti,sysc";
			phandle = <0xfc>;
			ranges = <0x00 0x53100000 0x1000>;
			reg = <0x53100100 0x04 0x53100110 0x04 0x53100114 0x04>;
			reg-names = "rev\0sysc\0syss";
			ti,sysc-mask = <0x03>;
			ti,sysc-sidle = <0x00 0x01 0x02>;
			ti,syss-mask = <0x01>;

			sham@0 {
				compatible = "ti,omap4-sham";
				dma-names = "rx";
				dmas = <0x24 0x24 0x00>;
				interrupts = <0x6d>;
				phandle = <0xfd>;
				reg = <0x00 0x200>;
				status = "okay";
			};
		};

		target-module@53500000 {
			#address-cells = <0x01>;
			#size-cells = <0x01>;
			clock-names = "fck";
			clocks = <0x07 0x70 0x00>;
			compatible = "ti,sysc-omap2\0ti,sysc";
			phandle = <0xfe>;
			ranges = <0x00 0x53500000 0x1000>;
			reg = <0x53500080 0x04 0x53500084 0x04 0x53500088 0x04>;
			reg-names = "rev\0sysc\0syss";
			ti,sysc-mask = <0x03>;
			ti,sysc-sidle = <0x00 0x01 0x02 0x03>;
			ti,syss-mask = <0x01>;

			aes@0 {
				compatible = "ti,omap4-aes";
				dma-names = "tx\0rx";
				dmas = <0x24 0x06 0x00 0x24 0x05 0x00>;
				interrupts = <0x67>;
				phandle = <0xff>;
				reg = <0x00 0xa0>;
				status = "okay";
			};
		};

		target-module@56000000 {
			#address-cells = <0x01>;
			#size-cells = <0x01>;
			clock-names = "fck";
			clocks = <0x64 0x04 0x00>;
			compatible = "ti,sysc-omap4\0ti,sysc";
			power-domains = <0x65>;
			ranges = <0x00 0x56000000 0x1000000>;
			reg = <0x5600fe00 0x04 0x5600fe10 0x04>;
			reg-names = "rev\0sysc";
			reset-names = "rstctrl";
			resets = <0x65 0x00>;
			ti,sysc-midle = <0x00 0x01 0x02>;
			ti,sysc-sidle = <0x00 0x01 0x02>;

			gpu@0 {
				compatible = "ti,omap3630-gpu\0img,powervr-sgx530";
				interrupts = <0x25>;
				reg = <0x00 0x10000>;
			};
		};
	};

	opp-table {
		compatible = "operating-points-v2-ti-cpu";
		phandle = <0x02>;
		syscon = <0x06>;

		opp-100-275000000 {
			opp-hz = <0x00 0x10642ac0>;
			opp-microvolt = <0x10c8e0 0x1072f0 0x111ed0>;
			opp-supported-hw = <0x01 0xff>;
			opp-suspend;
		};

		opp-100-300000000 {
			opp-hz = <0x00 0x11e1a300>;
			opp-microvolt = <0x10c8e0 0x1072f0 0x111ed0>;
			opp-supported-hw = <0x06 0x20>;
			opp-suspend;
		};

		opp-100-500000000 {
			opp-hz = <0x00 0x1dcd6500>;
			opp-microvolt = <0x10c8e0 0x1072f0 0x111ed0>;
			opp-supported-hw = <0x01 0xffff>;
		};

		opp-100-600000000 {
			opp-hz = <0x00 0x23c34600>;
			opp-microvolt = <0x10c8e0 0x1072f0 0x111ed0>;
			opp-supported-hw = <0x06 0x40>;
		};

		opp-1000000000 {
			opp-hz = <0x00 0x3b9aca00>;
			opp-microvolt = <0x1437c8 0x13d044 0x149f4c>;
			opp-supported-hw = <0x06 0x100>;
		};

		opp-120-600000000 {
			opp-hz = <0x00 0x23c34600>;
			opp-microvolt = <0x124f80 0x11f1c0 0x12ad40>;
			opp-supported-hw = <0x01 0xffff>;
		};

		opp-120-720000000 {
			opp-hz = <0x00 0x2aea5400>;
			opp-microvolt = <0x124f80 0x11f1c0 0x12ad40>;
			opp-supported-hw = <0x06 0x80>;
		};

		opp-50-300000000 {
			opp-hz = <0x00 0x11e1a300>;
			opp-microvolt = <0xe7ef0 0xe34b8 0xec928>;
			opp-supported-hw = <0x06 0x10>;
			opp-suspend;
		};

		opp-720000000 {
			opp-hz = <0x00 0x2aea5400>;
			opp-microvolt = <0x1339e0 0x12d770 0x139c50>;
			opp-supported-hw = <0x01 0xffff>;
		};

		opp-800000000 {
			opp-hz = <0x00 0x2faf0800>;
			opp-microvolt = <0x1339e0 0x12d770 0x139c50>;
			opp-supported-hw = <0x06 0x100>;
		};
	};

	soc {
		compatible = "ti,omap-infra";
	};

	sound {
		compatible = "simple-audio-card";
		simple-audio-card,bitclock-master = <0x68>;
		simple-audio-card,format = "i2s";
		simple-audio-card,frame-master = <0x68>;
		simple-audio-card,name = "TI BeagleBone Black";

		simple-audio-card,codec {
			sound-dai = <0x6b>;
		};

		simple-audio-card,cpu {
			clocks = <0x6a>;
			phandle = <0x68>;
			sound-dai = <0x69>;
		};
	};

	target-module@4b000000 {
		#address-cells = <0x01>;
		#size-cells = <0x01>;
		clock-names = "fck";
		clocks = <0x07 0xb8 0x00>;
		compatible = "ti,sysc-omap4-simple\0ti,sysc";
		ranges = <0x00 0x4b000000 0x1000000>;
		ti,no-idle;

		target-module@140000 {
			#address-cells = <0x01>;
			#size-cells = <0x01>;
			clock-names = "fck";
			clocks = <0x08 0x00 0x00>;
			compatible = "ti,sysc-omap4-simple\0ti,sysc";
			ranges = <0x00 0x140000 0xec0000>;

			pmu@0 {
				compatible = "arm,cortex-a8-pmu";
				interrupts = <0x03>;
			};
		};
	};
};
